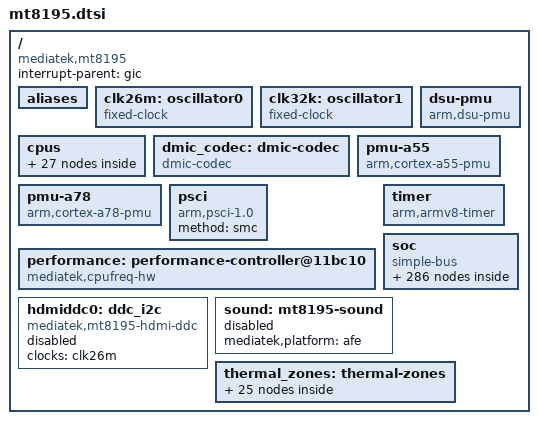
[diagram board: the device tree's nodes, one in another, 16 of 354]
// SPDX-License-Identifier: (GPL-2.0 OR MIT)
/*
 * Copyright (c) 2021 MediaTek Inc.
 * Author: Seiya Wang <seiya.wang@mediatek.com>
 */

/dts-v1/;
#include <dt-bindings/clock/mt8195-clk.h>
#include <dt-bindings/gce/mt8195-gce.h>
#include <dt-bindings/interrupt-controller/arm-gic.h>
#include <dt-bindings/interrupt-controller/irq.h>
#include <dt-bindings/memory/mt8195-memory-port.h>
#include <dt-bindings/phy/phy.h>
#include <dt-bindings/pinctrl/mt8195-pinfunc.h>
#include <dt-bindings/power/mt8195-power.h>
#include <dt-bindings/reset/ti-syscon.h>
#include <dt-bindings/reset/mt8195-resets.h>
#include <dt-bindings/thermal/thermal.h>

/ {
	compatible = "mediatek,mt8195";
	interrupt-parent = <&gic>;
	#address-cells = <2>;
	#size-cells = <2>;

	aliases {
		dpi1 = &disp_dpi1;
		dp-intf0 = &dp_intf0;
		dp-intf1 = &dp_intf1;
		ethdr0 = &ethdr0;
		gce0 = &gce0;
		gce1 = &gce1;
		mutex0 = &mutex;
		mutex1 = &mutex1;
		merge1 = &merge1;
		merge2 = &merge2;
		merge3 = &merge3;
		merge4 = &merge4;
		merge5 = &merge5;
		vdo1_rdma0 = &vdo1_rdma0;
		vdo1_rdma1 = &vdo1_rdma1;
		vdo1_rdma2 = &vdo1_rdma2;
		vdo1_rdma3 = &vdo1_rdma3;
		vdo1_rdma4 = &vdo1_rdma4;
		vdo1_rdma5 = &vdo1_rdma5;
		vdo1_rdma6 = &vdo1_rdma6;
		vdo1_rdma7 = &vdo1_rdma7;
	};

	clk26m: oscillator0 {
		compatible = "fixed-clock";
		#clock-cells = <0>;
		clock-frequency = <26000000>;
		clock-output-names = "clk26m";
	};

	clk32k: oscillator1 {
		compatible = "fixed-clock";
		#clock-cells = <0>;
		clock-frequency = <32768>;
		clock-output-names = "clk32k";
	};

	cpus {
		#address-cells = <1>;
		#size-cells = <0>;

		cpu0: cpu@0 {
			device_type = "cpu";
			compatible = "arm,cortex-a55", "arm,armv8";
			reg = <0x000>;
			enable-method = "psci";
			performance-domains = <&performance 0>;
			clock-frequency = <1701000000>;
			capacity-dmips-mhz = <578>;
			cpu-idle-states = <&cpuoff_l &clusteroff_l>;
			next-level-cache = <&l2_0>;
			#cooling-cells = <2>;
		};

		cpu1: cpu@100 {
			device_type = "cpu";
			compatible = "arm,cortex-a55", "arm,armv8";
			reg = <0x100>;
			enable-method = "psci";
			performance-domains = <&performance 0>;
			clock-frequency = <1701000000>;
			capacity-dmips-mhz = <578>;
			cpu-idle-states = <&cpuoff_l &clusteroff_l>;
			next-level-cache = <&l2_0>;
			#cooling-cells = <2>;
		};

		cpu2: cpu@200 {
			device_type = "cpu";
			compatible = "arm,cortex-a55", "arm,armv8";
			reg = <0x200>;
			enable-method = "psci";
			performance-domains = <&performance 0>;
			clock-frequency = <1701000000>;
			capacity-dmips-mhz = <578>;
			cpu-idle-states = <&cpuoff_l &clusteroff_l>;
			next-level-cache = <&l2_0>;
			#cooling-cells = <2>;
		};

		cpu3: cpu@300 {
			device_type = "cpu";
			compatible = "arm,cortex-a55", "arm,armv8";
			reg = <0x300>;
			enable-method = "psci";
			performance-domains = <&performance 0>;
			clock-frequency = <1701000000>;
			capacity-dmips-mhz = <578>;
			cpu-idle-states = <&cpuoff_l &clusteroff_l>;
			next-level-cache = <&l2_0>;
			#cooling-cells = <2>;
		};

		cpu4: cpu@400 {
			device_type = "cpu";
			compatible = "arm,cortex-a78", "arm,armv8";
			reg = <0x400>;
			enable-method = "psci";
			performance-domains = <&performance 1>;
			clock-frequency = <2171000000>;
			capacity-dmips-mhz = <1024>;
			cpu-idle-states = <&cpuoff_b &clusteroff_b>;
			next-level-cache = <&l2_1>;
			#cooling-cells = <2>;
		};

		cpu5: cpu@500 {
			device_type = "cpu";
			compatible = "arm,cortex-a78", "arm,armv8";
			reg = <0x500>;
			enable-method = "psci";
			performance-domains = <&performance 1>;
			clock-frequency = <2171000000>;
			capacity-dmips-mhz = <1024>;
			cpu-idle-states = <&cpuoff_b &clusteroff_b>;
			next-level-cache = <&l2_1>;
			#cooling-cells = <2>;
		};

		cpu6: cpu@600 {
			device_type = "cpu";
			compatible = "arm,cortex-a78", "arm,armv8";
			reg = <0x600>;
			enable-method = "psci";
			performance-domains = <&performance 1>;
			clock-frequency = <2171000000>;
			capacity-dmips-mhz = <1024>;
			cpu-idle-states = <&cpuoff_b &clusteroff_b>;
			next-level-cache = <&l2_1>;
			#cooling-cells = <2>;
		};

		cpu7: cpu@700 {
			device_type = "cpu";
			compatible = "arm,cortex-a78", "arm,armv8";
			reg = <0x700>;
			enable-method = "psci";
			performance-domains = <&performance 1>;
			clock-frequency = <2171000000>;
			capacity-dmips-mhz = <1024>;
			cpu-idle-states = <&cpuoff_b &clusteroff_b>;
			next-level-cache = <&l2_1>;
			#cooling-cells = <2>;
		};

		cpu-map {
			cluster0 {
				core0 {
					cpu = <&cpu0>;
				};
				core1 {
					cpu = <&cpu1>;
				};
				core2 {
					cpu = <&cpu2>;
				};
				core3 {
					cpu = <&cpu3>;
				};
			};
			cluster1 {
				core0 {
					cpu = <&cpu4>;
				};
				core1 {
					cpu = <&cpu5>;
				};
				core2 {
					cpu = <&cpu6>;
				};
				core3 {
					cpu = <&cpu7>;
				};
			};
		};

		idle-states {
			entry-method = "arm,psci";
			cpuoff_l: cpuoff_l {
				compatible = "arm,idle-state";
				arm,psci-suspend-param = <0x00010001>;
				local-timer-stop;
				entry-latency-us = <50>;
				exit-latency-us = <95>;
				min-residency-us = <580>;
			};
			cpuoff_b: cpuoff_b {
				compatible = "arm,idle-state";
				arm,psci-suspend-param = <0x00010001>;
				local-timer-stop;
				entry-latency-us = <45>;
				exit-latency-us = <140>;
				min-residency-us = <740>;
			};
			clusteroff_l: clusteroff_l {
				compatible = "arm,idle-state";
				arm,psci-suspend-param = <0x01010002>;
				local-timer-stop;
				entry-latency-us = <55>;
				exit-latency-us = <155>;
				min-residency-us = <840>;
			};
			clusteroff_b: clusteroff_b {
				compatible = "arm,idle-state";
				arm,psci-suspend-param = <0x01010002>;
				local-timer-stop;
				entry-latency-us = <50>;
				exit-latency-us = <200>;
				min-residency-us = <1000>;
			};
		};

		l2_0: l2-cache0 {
			compatible = "cache";
			next-level-cache = <&l3_0>;
		};

		l2_1: l2-cache1 {
			compatible = "cache";
			next-level-cache = <&l3_0>;
		};

		l3_0: l3-cache {
			compatible = "cache";
		};
	};

	dsu-pmu {
		compatible = "arm,dsu-pmu";
		interrupts = <GIC_SPI 18 IRQ_TYPE_LEVEL_HIGH 0>;
		cpus = <&cpu0>, <&cpu1>, <&cpu2>, <&cpu3>,
		       <&cpu4>, <&cpu5>, <&cpu6>, <&cpu7>;
	};

	dmic_codec: dmic-codec {
		compatible = "dmic-codec";
		num-channels = <2>;
		wakeup-delay-ms = <50>;
	};

	pmu-a55 {
		compatible = "arm,cortex-a55-pmu";
		interrupt-parent = <&gic>;
		interrupts = <GIC_PPI 7 IRQ_TYPE_LEVEL_HIGH &ppi_cluster0>;
	};

	pmu-a78 {
		compatible = "arm,cortex-a78-pmu";
		interrupt-parent = <&gic>;
		interrupts = <GIC_PPI 7 IRQ_TYPE_LEVEL_HIGH &ppi_cluster1>;
	};

	psci {
		compatible = "arm,psci-1.0";
		method = "smc";
	};

        performance: performance-controller@11bc10 {
                compatible = "mediatek,cpufreq-hw";
                reg = <0 0x0011bc10 0 0x120>, <0 0x0011bd30 0 0x120>;
                #performance-domain-cells = <1>;
        };

	timer: timer {
		compatible = "arm,armv8-timer";
		interrupt-parent = <&gic>;
		interrupts = <GIC_PPI 13 IRQ_TYPE_LEVEL_HIGH 0>,
			     <GIC_PPI 14 IRQ_TYPE_LEVEL_HIGH 0>,
			     <GIC_PPI 11 IRQ_TYPE_LEVEL_HIGH 0>,
			     <GIC_PPI 10 IRQ_TYPE_LEVEL_HIGH 0>;
		clock-frequency = <13000000>;
	};

	soc {
		#address-cells = <2>;
		#size-cells = <2>;
		compatible = "simple-bus";
		ranges;

		gic: interrupt-controller@c000000 {
			compatible = "arm,gic-v3";
			#interrupt-cells = <4>;
			#redistributor-regions = <1>;
			interrupt-parent = <&gic>;
			interrupt-controller;
			reg = <0 0x0c000000 0 0x40000>,
			      <0 0x0c040000 0 0x200000>;
			interrupts = <GIC_PPI 9 IRQ_TYPE_LEVEL_HIGH 0>;

			ppi-partitions {
				ppi_cluster0: interrupt-partition-0 {
					affinity = <&cpu0 &cpu1 &cpu2 &cpu3>;
				};
				ppi_cluster1: interrupt-partition-1 {
					affinity = <&cpu4 &cpu5 &cpu6 &cpu7>;
				};
			};
		};

		topckgen: syscon@10000000 {
			compatible = "mediatek,mt8195-topckgen", "syscon";
			reg = <0 0x10000000 0 0x1000>;
			#clock-cells = <1>;
		};

		infracfg_ao: syscon@10001000 {
			compatible = "mediatek,mt8195-infracfg_ao", "syscon", "simple-mfd";
			reg = <0 0x10001000 0 0x1000>;
			#clock-cells = <1>;
			infracfg_rst: reset-controller {
				compatible = "ti,syscon-reset";
				#reset-cells = <1>;
				ti,reset-bits = <
					0x140 18 0x144 18 0 0 (ASSERT_SET | DEASSERT_SET | STATUS_NONE)
					0x120 0 0x124 0 0 0     (ASSERT_SET | DEASSERT_SET | STATUS_NONE)
					0x730 10 0x734 10 0 0     (ASSERT_SET | DEASSERT_SET | STATUS_NONE)
					0x150 5 0x154 5 0 0     (ASSERT_SET | DEASSERT_SET | STATUS_NONE)
				>;
			};
		};

		pericfg: syscon@10003000 {
			compatible = "mediatek,mt8195-pericfg", "syscon";
			reg = <0 0x10003000 0 0x1000>;
			#clock-cells = <1>;
		};

		pio: pinctrl@10005000 {
			compatible = "mediatek,mt8195-pinctrl";
			reg = <0 0x10005000 0 0x1000>,
			      <0 0x11d10000 0 0x1000>,
			      <0 0x11d30000 0 0x1000>,
			      <0 0x11d40000 0 0x1000>,
			      <0 0x11e20000 0 0x1000>,
			      <0 0x11eb0000 0 0x1000>,
			      <0 0x11f40000 0 0x1000>,
			      <0 0x1000b000 0 0x1000>;
			reg-names = "iocfg0", "iocfg_bm", "iocfg_bl",
				    "iocfg_br", "iocfg_lm", "iocfg_rb",
				    "iocfg_tl", "eint";
			gpio-controller;
			#gpio-cells = <2>;
			gpio-ranges = <&pio 0 0 144>;
			interrupt-controller;
			interrupts = <GIC_SPI 235 IRQ_TYPE_LEVEL_HIGH 0>;
			#interrupt-cells = <2>;
		};

		scpsys: syscon@10006000 {
			compatible = "syscon", "simple-mfd";
			reg = <0 0x10006000 0 0x1000>;
			#power-domain-cells = <1>;

			/* System Power Manager */
			spm: power-controller {
				compatible = "mediatek,mt8195-power-controller";
				#address-cells = <1>;
				#size-cells = <0>;
				#power-domain-cells = <1>;

				/* power domain of the SoC */
				mfg0: power-domain@MT8195_POWER_DOMAIN_MFG0 {
					reg = <MT8195_POWER_DOMAIN_MFG0>;
					#address-cells = <1>;
					#size-cells = <0>;
					#power-domain-cells = <1>;

					power-domain@MT8195_POWER_DOMAIN_MFG1 {
						reg = <MT8195_POWER_DOMAIN_MFG1>;
						clocks = <&apmixedsys CLK_APMIXED_MFGPLL>;
						clock-names = "mfg";
						mediatek,infracfg = <&infracfg_ao>;
						#address-cells = <1>;
						#size-cells = <0>;
						#power-domain-cells = <1>;

						power-domain@MT8195_POWER_DOMAIN_MFG2 {
							reg = <MT8195_POWER_DOMAIN_MFG2>;
							#power-domain-cells = <0>;
						};

						power-domain@MT8195_POWER_DOMAIN_MFG3 {
							reg = <MT8195_POWER_DOMAIN_MFG3>;
							#power-domain-cells = <0>;
						};

						power-domain@MT8195_POWER_DOMAIN_MFG4 {
							reg = <MT8195_POWER_DOMAIN_MFG4>;
							#power-domain-cells = <0>;
						};

						power-domain@MT8195_POWER_DOMAIN_MFG5 {
							reg = <MT8195_POWER_DOMAIN_MFG5>;
							#power-domain-cells = <0>;
						};

						power-domain@MT8195_POWER_DOMAIN_MFG6 {
							reg = <MT8195_POWER_DOMAIN_MFG6>;
							#power-domain-cells = <0>;
						};
					};
				};

				power-domain@MT8195_POWER_DOMAIN_VPPSYS0 {
					reg = <MT8195_POWER_DOMAIN_VPPSYS0>;
					clocks = <&topckgen CLK_TOP_VPP>,
						 <&topckgen CLK_TOP_CAM>,
						 <&topckgen CLK_TOP_CCU>,
						 <&topckgen CLK_TOP_IMG>,
						 <&topckgen CLK_TOP_VENC>,
						 <&topckgen CLK_TOP_VDEC>,
						 <&topckgen CLK_TOP_WPE_VPP>,
						 <&topckgen CLK_TOP_CFG_VPP0>,
						 <&vppsys0 CLK_VPP0_SMI_COMMON>,
						 <&vppsys0 CLK_VPP0_GALS_VDO0_LARB0>,
						 <&vppsys0 CLK_VPP0_GALS_VDO0_LARB1>,
						 <&vppsys0 CLK_VPP0_GALS_VENCSYS>,
						 <&vppsys0 CLK_VPP0_GALS_VENCSYS_CORE1>,
						 <&vppsys0 CLK_VPP0_GALS_INFRA>,
						 <&vppsys0 CLK_VPP0_GALS_CAMSYS>,
						 <&vppsys0 CLK_VPP0_GALS_VPP1_LARB5>,
						 <&vppsys0 CLK_VPP0_GALS_VPP1_LARB6>,
						 <&vppsys0 CLK_VPP0_SMI_REORDER>,
						 <&vppsys0 CLK_VPP0_SMI_IOMMU>,
						 <&vppsys0 CLK_VPP0_GALS_IMGSYS_CAMSYS>,
						 <&vppsys0 CLK_VPP0_GALS_EMI0_EMI1>,
						 <&vppsys0 CLK_VPP0_SMI_SUB_COMMON_REORDER>,
						 <&vppsys0 CLK_VPP0_SMI_RSI>,
						 <&vppsys0 CLK_VPP0_SMI_COMMON_LARB4>,
						 <&vppsys0 CLK_VPP0_GALS_VDEC_VDEC_CORE1>,
						 <&vppsys0 CLK_VPP0_GALS_VPP1_WPE>,
						 <&vppsys0 CLK_VPP0_GALS_VDO0_VDO1_VENCSYS_CORE1>;
					clock-names = "vppsys", "vppsys1", "vppsys2", "vppsys3",
						      "vppsys4", "vppsys5", "vppsys6", "vppsys7",
						      "vppsys0-0", "vppsys0-1", "vppsys0-2", "vppsys0-3",
						      "vppsys0-4", "vppsys0-5", "vppsys0-6", "vppsys0-7",
						      "vppsys0-8", "vppsys0-9", "vppsys0-10", "vppsys0-11",
						      "vppsys0-12", "vppsys0-13", "vppsys0-14",
						      "vppsys0-15", "vppsys0-16", "vppsys0-17",
						      "vppsys0-18";
					mediatek,infracfg = <&infracfg_ao>;
					#address-cells = <1>;
					#size-cells = <0>;
					#power-domain-cells = <1>;

					power-domain@MT8195_POWER_DOMAIN_VDEC1 {
						reg = <MT8195_POWER_DOMAIN_VDEC1>;
						clocks = <&vdecsys CLK_VDEC_LARB1>;
						clock-names = "vdec1-0";
						mediatek,infracfg = <&infracfg_ao>;
						#power-domain-cells = <0>;
					};

					power-domain@MT8195_POWER_DOMAIN_VENC_CORE1 {
						reg = <MT8195_POWER_DOMAIN_VENC_CORE1>;
						mediatek,infracfg = <&infracfg_ao>;
						#power-domain-cells = <0>;
					};

					power-domain@MT8195_POWER_DOMAIN_VDOSYS0 {
						reg = <MT8195_POWER_DOMAIN_VDOSYS0>;
						clocks = <&topckgen CLK_TOP_CFG_VDO0>,
							 <&vdosys0 CLK_VDO0_SMI_GALS>,
							 <&vdosys0 CLK_VDO0_SMI_COMMON>,
							 <&vdosys0 CLK_VDO0_SMI_EMI>,
							 <&vdosys0 CLK_VDO0_SMI_IOMMU>,
							 <&vdosys0 CLK_VDO0_SMI_LARB>,
							 <&vdosys0 CLK_VDO0_SMI_RSI>;
						clock-names = "vdosys0", "vdosys0-0", "vdosys0-1",
							      "vdosys0-2", "vdosys0-3",
							      "vdosys0-4", "vdosys0-5";
						mediatek,infracfg = <&infracfg_ao>;
						#address-cells = <1>;
						#size-cells = <0>;
						#power-domain-cells = <1>;

						power-domain@MT8195_POWER_DOMAIN_VPPSYS1 {
							reg = <MT8195_POWER_DOMAIN_VPPSYS1>;
							clocks = <&topckgen CLK_TOP_CFG_VPP1>,
								 <&vppsys1 CLK_VPP1_VPPSYS1_GALS>,
								 <&vppsys1 CLK_VPP1_VPPSYS1_LARB>;
							clock-names = "vppsys1", "vppsys1-0",
								      "vppsys1-1";
							mediatek,infracfg = <&infracfg_ao>;
							#power-domain-cells = <0>;
						};

						power-domain@MT8195_POWER_DOMAIN_WPESYS {
							reg = <MT8195_POWER_DOMAIN_WPESYS>;
							clocks = <&wpesys CLK_WPE_SMI_LARB7>,
								 <&wpesys CLK_WPE_SMI_LARB8>,
								 <&wpesys CLK_WPE_SMI_LARB7_P>,
								 <&wpesys CLK_WPE_SMI_LARB8_P>;
							clock-names = "wepsys-0", "wepsys-1", "wepsys-2",
								      "wepsys-3";
							mediatek,infracfg = <&infracfg_ao>;
							#power-domain-cells = <0>;
						};

						power-domain@MT8195_POWER_DOMAIN_VDEC0 {
							reg = <MT8195_POWER_DOMAIN_VDEC0>;
							clocks = <&vdecsys_soc CLK_VDEC_SOC_LARB1>;
							clock-names = "vdec0-0";
							mediatek,infracfg = <&infracfg_ao>;
							#power-domain-cells = <0>;
						};

						power-domain@MT8195_POWER_DOMAIN_VDEC2 {
							reg = <MT8195_POWER_DOMAIN_VDEC2>;
							clocks = <&vdecsys_core1 CLK_VDEC_CORE1_LARB1>;
							clock-names = "vdec2-0";
							mediatek,infracfg = <&infracfg_ao>;
							#power-domain-cells = <0>;
						};

						power-domain@MT8195_POWER_DOMAIN_VENC {
							reg = <MT8195_POWER_DOMAIN_VENC>;
							mediatek,infracfg = <&infracfg_ao>;
							#power-domain-cells = <0>;
						};

						power-domain@MT8195_POWER_DOMAIN_VDOSYS1 {
							reg = <MT8195_POWER_DOMAIN_VDOSYS1>;
							clocks = <&topckgen CLK_TOP_CFG_VDO1>,
								 <&vdosys1 CLK_VDO1_SMI_LARB2>,
								 <&vdosys1 CLK_VDO1_SMI_LARB3>,
								 <&vdosys1 CLK_VDO1_GALS>;
							clock-names = "vdosys1", "vdosys1-0",
								      "vdosys1-1", "vdosys1-2";
							mediatek,infracfg = <&infracfg_ao>;
							#address-cells = <1>;
							#size-cells = <0>;
							#power-domain-cells = <1>;

							power-domain@MT8195_POWER_DOMAIN_DP_TX {
								reg = <MT8195_POWER_DOMAIN_DP_TX>;
								mediatek,infracfg = <&infracfg_ao>;
								#power-domain-cells = <0>;
							};

							power-domain@MT8195_POWER_DOMAIN_EPD_TX {
								reg = <MT8195_POWER_DOMAIN_EPD_TX>;
								mediatek,infracfg = <&infracfg_ao>;
								#power-domain-cells = <0>;
							};

							power-domain@MT8195_POWER_DOMAIN_HDMI_TX {
								reg = <MT8195_POWER_DOMAIN_HDMI_TX>;
								clocks = <&topckgen CLK_TOP_HDMI_APB>;
								clock-names = "hdmi_tx";
								#power-domain-cells = <0>;
							};
						};

						power-domain@MT8195_POWER_DOMAIN_IMG {
							reg = <MT8195_POWER_DOMAIN_IMG>;
							clocks = <&imgsys CLK_IMG_LARB9>,
								 <&imgsys CLK_IMG_GALS>;
							clock-names = "img-0", "img-1";
							mediatek,infracfg = <&infracfg_ao>;
							#address-cells = <1>;
							#size-cells = <0>;
							#power-domain-cells = <1>;

							power-domain@MT8195_POWER_DOMAIN_DIP {
								reg = <MT8195_POWER_DOMAIN_DIP>;
								#power-domain-cells = <0>;
							};

							power-domain@MT8195_POWER_DOMAIN_IPE {
								reg = <MT8195_POWER_DOMAIN_IPE>;
								clocks = <&topckgen CLK_TOP_IPE>,
									 <&imgsys CLK_IMG_IPE>,
									 <&ipesys CLK_IPE_SMI_LARB12>;
								clock-names = "ipe", "ipe-0", "ipe-1";
								mediatek,infracfg = <&infracfg_ao>;
								#power-domain-cells = <0>;
							};
						};

						power-domain@MT8195_POWER_DOMAIN_CAM {
							reg = <MT8195_POWER_DOMAIN_CAM>;
							clocks = <&camsys CLK_CAM_LARB13>,
								 <&camsys CLK_CAM_LARB14>,
								 <&camsys CLK_CAM_CAM2MM0_GALS>,
								 <&camsys CLK_CAM_CAM2MM1_GALS>,
								 <&camsys CLK_CAM_CAM2SYS_GALS>;
							clock-names = "cam-0", "cam-1", "cam-2", "cam-3",
								      "cam-4";
							mediatek,infracfg = <&infracfg_ao>;
							#address-cells = <1>;
							#size-cells = <0>;
							#power-domain-cells = <1>;

							power-domain@MT8195_POWER_DOMAIN_CAM_RAWA {
								reg = <MT8195_POWER_DOMAIN_CAM_RAWA>;
								#power-domain-cells = <0>;
							};

							power-domain@MT8195_POWER_DOMAIN_CAM_RAWB {
								reg = <MT8195_POWER_DOMAIN_CAM_RAWB>;
								#power-domain-cells = <0>;
							};

							power-domain@MT8195_POWER_DOMAIN_CAM_MRAW {
								reg = <MT8195_POWER_DOMAIN_CAM_MRAW>;
								#power-domain-cells = <0>;
							};
						};
					};
				};

				power-domain@MT8195_POWER_DOMAIN_PCIE_MAC_P0 {
					reg = <MT8195_POWER_DOMAIN_PCIE_MAC_P0>;
					mediatek,infracfg = <&infracfg_ao>;
					#power-domain-cells = <0>;
				};

				power-domain@MT8195_POWER_DOMAIN_PCIE_MAC_P1 {
					reg = <MT8195_POWER_DOMAIN_PCIE_MAC_P1>;
					mediatek,infracfg = <&infracfg_ao>;
					#power-domain-cells = <0>;
				};

				power-domain@MT8195_POWER_DOMAIN_PCIE_PHY {
					reg = <MT8195_POWER_DOMAIN_PCIE_PHY>;
					#power-domain-cells = <0>;
				};

				power-domain@MT8195_POWER_DOMAIN_SSUSB_PCIE_PHY {
					reg = <MT8195_POWER_DOMAIN_SSUSB_PCIE_PHY>;
					#power-domain-cells = <0>;
				};

				power-domain@MT8195_POWER_DOMAIN_CSI_RX_TOP {
					reg = <MT8195_POWER_DOMAIN_CSI_RX_TOP>;
					clocks = <&topckgen CLK_TOP_SENINF>,
						 <&topckgen CLK_TOP_SENINF2>;
					clock-names = "csi_rx_top", "csi_rx_top1";
					#power-domain-cells = <0>;
				};

				power-domain@MT8195_POWER_DOMAIN_ETHER {
					reg = <MT8195_POWER_DOMAIN_ETHER>;
					clocks = <&pericfg_ao CLK_PERI_AO_ETHERNET_MAC>;
					clock-names = "ether";
					#power-domain-cells = <0>;
				};

				power-domain@MT8195_POWER_DOMAIN_ADSP {
					reg = <MT8195_POWER_DOMAIN_ADSP>;
					clocks = <&topckgen CLK_TOP_ADSP>,
						 <&topckgen CLK_TOP_AUDIO_LOCAL_BUS>;
					clock-names = "adsp", "adsp1";
					#address-cells = <1>;
					#size-cells = <0>;
					mediatek,infracfg = <&infracfg_ao>;
					#power-domain-cells = <1>;

					power-domain@MT8195_POWER_DOMAIN_AUDIO {
						reg = <MT8195_POWER_DOMAIN_AUDIO>;
						clocks = <&topckgen CLK_TOP_A1SYS_HP>,
							 <&topckgen CLK_TOP_AUD_INTBUS>,
							 <&topckgen CLK_TOP_AUDIO_LOCAL_BUS>,
							 <&infracfg_ao CLK_INFRA_AO_AUDIO_26M_B>;
						clock-names = "audio", "audio1", "audio2",
							      "audio3";
						mediatek,infracfg = <&infracfg_ao>;
						#power-domain-cells = <0>;
					};
				};
			};
		};

		watchdog: watchdog@10007000 {
			compatible = "mediatek,mt8195-wdt",
				     "mediatek,mt6589-wdt";
			mediatek,disable-extrst;
			reg = <0 0x10007000 0 0x100>;
		};

		apmixedsys: syscon@1000c000 {
			compatible = "mediatek,mt8195-apmixedsys", "syscon";
			reg = <0 0x1000c000 0 0x1000>;
			#clock-cells = <1>;
		};

		cec: cec@10014000 {
			compatible = "mediatek,mt8195-cec";
			reg = <0 0x10014000 0 0x100>;
			interrupts = <GIC_SPI 680 IRQ_TYPE_LEVEL_HIGH 0>;
			clocks = <&infracfg_ao CLK_INFRA_AO_CEC_66M_H>,
				 <&infracfg_ao CLK_INFRA_AO_CEC_66M_B>,
				 <&infracfg_ao CLK_INFRA_AO_HDMI_32K>,
				 <&infracfg_ao CLK_INFRA_AO_HDMI_26M>;
			clock-names = "cec_66m_h",
				      "cec_66m_b",
				      "hdmi_32k",
				      "hdmi_26m";
			hdmi = <&hdmi0>;
		};

		systimer: timer@10017000 {
			compatible = "mediatek,mt8195-timer",
				     "mediatek,mt6765-timer";
			reg = <0 0x10017000 0 0x1000>;
			interrupts = <GIC_SPI 265 IRQ_TYPE_LEVEL_HIGH 0>;
			clocks = <&topckgen CLK_TOP_CLK26M_D2>;
		};

		pwrap: pwrap@10024000 {
			compatible = "mediatek,mt8195-pwrap", "syscon";
			reg = <0 0x10024000 0 0x1000>;
			reg-names = "pwrap";
			interrupts = <GIC_SPI 243 IRQ_TYPE_LEVEL_HIGH 0>;
			clocks = <&infracfg_ao CLK_INFRA_AO_PMIC_AP>,
				 <&infracfg_ao CLK_INFRA_AO_PMIC_TMR>;
			clock-names = "spi", "wrap";
			assigned-clocks = <&topckgen CLK_TOP_PWRAP_ULPOSC>;
			assigned-clock-parents = <&topckgen CLK_TOP_ULPOSC1_D10>;
		};

		spmi: spmi@10027000 {
			compatible = "mediatek,mt8195-spmi";
			reg = <0 0x10027000 0 0x000e00>,
			      <0 0x10029000 0 0x000100>;
			reg-names = "pmif", "spmimst";
			clocks = <&infracfg_ao CLK_INFRA_AO_PMIC_AP>,
				 <&infracfg_ao CLK_INFRA_AO_PMIC_TMR>,
				 <&topckgen CLK_TOP_SPMI_M_MST>;
			clock-names = "pmif_sys_ck",
				      "pmif_tmr_ck",
				      "spmimst_clk_mux";
			assigned-clocks = <&topckgen CLK_TOP_PWRAP_ULPOSC>;
			assigned-clock-parents = <&topckgen CLK_TOP_ULPOSC1_D10>;
		};

		iommu_infra: infra-iommu@10315000 {
			compatible = "mediatek,mt8195-iommu-infra";
			reg = <0 0x10315000 0 0x5000>;
			interrupts = <GIC_SPI 795 IRQ_TYPE_LEVEL_HIGH 0>,
				     <GIC_SPI 796 IRQ_TYPE_LEVEL_HIGH 0>,
				     <GIC_SPI 797 IRQ_TYPE_LEVEL_HIGH 0>,
				     <GIC_SPI 798 IRQ_TYPE_LEVEL_HIGH 0>,
				     <GIC_SPI 799 IRQ_TYPE_LEVEL_HIGH 0>;
			clocks = <&clk26m>;
			clock-names = "bclk";
			#iommu-cells = <1>;
		};

		gce0: disp_mailbox@10320000 {
			compatible = "mediatek,mt8195-gce";
			reg = <0 0x10320000 0 0x4000>;
			interrupts = <GIC_SPI 226 IRQ_TYPE_LEVEL_HIGH 0>;
			#mbox-cells = <2>;
			clocks = <&infracfg_ao CLK_INFRA_AO_GCE>;
		};

		gce1: mdp_mailbox@10330000 {
			compatible = "mediatek,mt8195-gce";
			reg = <0 0x10330000 0 0x4000>;
			interrupts = <GIC_SPI 228 IRQ_TYPE_LEVEL_HIGH 0>;
			#mbox-cells = <2>;
			clocks = <&infracfg_ao CLK_INFRA_AO_GCE2>;
		};

		scp: scp@10500000 {
			compatible = "mediatek,mt8195-scp";
			reg = <0 0x10500000 0 0x100000>,
			      <0 0x10700000 0 0x8000>,
			      <0 0x10720000 0 0xe0000>;
			reg-names = "sram", "l1tcm", "cfg";
			interrupts = <GIC_SPI 462 IRQ_TYPE_LEVEL_HIGH 0>;
			status = "okay";
		};

		scp_adsp: clock-controller@10720000 {
			compatible = "mediatek,mt8195-scp_adsp";
			reg = <0 0x10720000 0 0x1000>;
			#clock-cells = <1>;
		};

		afe: mt8195-afe-pcm@10890000 {
			compatible = "mediatek,mt8195-audio";
			reg = <0 0x10890000 0 0x10000>;
			mediatek,topckgen = <&topckgen>;
			power-domains = <&spm MT8195_POWER_DOMAIN_AUDIO>;
			interrupts = <GIC_SPI 822 IRQ_TYPE_LEVEL_HIGH 0>;
			clocks = <&clk26m>,
				<&apmixedsys CLK_APMIXED_APLL1>,
				<&apmixedsys CLK_APMIXED_APLL2>,
				<&topckgen CLK_TOP_APLL12_DIV0>,
				<&topckgen CLK_TOP_APLL12_DIV1>,
				<&topckgen CLK_TOP_APLL12_DIV2>,
				<&topckgen CLK_TOP_APLL12_DIV3>,
				<&topckgen CLK_TOP_APLL12_DIV9>,
				<&topckgen CLK_TOP_A1SYS_HP>,
				<&topckgen CLK_TOP_AUD_INTBUS>,
				<&topckgen CLK_TOP_AUDIO_H>,
				<&topckgen CLK_TOP_AUDIO_LOCAL_BUS>,
				<&topckgen CLK_TOP_DPTX_MCK>,
				<&topckgen CLK_TOP_I2SO1_MCK>,
				<&topckgen CLK_TOP_I2SO2_MCK>,
				<&topckgen CLK_TOP_I2SI1_MCK>,
				<&topckgen CLK_TOP_I2SI2_MCK>,
				<&infracfg_ao CLK_INFRA_AO_AUDIO_26M_B>,
				<&scp_adsp CLK_SCP_ADSP_AUDIODSP>;
			clock-names = "clk26m",
				"apll1_ck",
				"apll2_ck",
				"apll12_div0",
				"apll12_div1",
				"apll12_div2",
				"apll12_div3",
				"apll12_div9",
				"a1sys_hp_sel",
				"aud_intbus_sel",
				"audio_h_sel",
				"audio_local_bus_sel",
				"dptx_m_sel",
				"i2so1_m_sel",
				"i2so2_m_sel",
				"i2si1_m_sel",
				"i2si2_m_sel",
				"infra_ao_audio_26m_b",
				"scp_adsp_audiodsp";
			status = "disabled";
		};

		uart0: serial@11001100 {
			compatible = "mediatek,mt8195-uart",
				     "mediatek,mt6577-uart";
			reg = <0 0x11001100 0 0x100>;
			interrupts = <GIC_SPI 141 IRQ_TYPE_LEVEL_HIGH 0>;
			clocks = <&clk26m>, <&infracfg_ao CLK_INFRA_AO_UART0>;
			clock-names = "baud", "bus";
			status = "disabled";
		};

		uart1: serial@11001200 {
			compatible = "mediatek,mt8195-uart",
				     "mediatek,mt6577-uart";
			reg = <0 0x11001200 0 0x100>;
			interrupts = <GIC_SPI 142 IRQ_TYPE_LEVEL_HIGH 0>;
			clocks = <&clk26m>, <&infracfg_ao CLK_INFRA_AO_UART1>;
			clock-names = "baud", "bus";
			status = "disabled";
		};

		uart2: serial@11001300 {
			compatible = "mediatek,mt8195-uart",
				     "mediatek,mt6577-uart";
			reg = <0 0x11001300 0 0x100>;
			interrupts = <GIC_SPI 143 IRQ_TYPE_LEVEL_HIGH 0>;
			clocks = <&clk26m>, <&infracfg_ao CLK_INFRA_AO_UART2>;
			clock-names = "baud", "bus";
			status = "disabled";
		};

		uart3: serial@11001400 {
			compatible = "mediatek,mt8195-uart",
				     "mediatek,mt6577-uart";
			reg = <0 0x11001400 0 0x100>;
			interrupts = <GIC_SPI 723 IRQ_TYPE_LEVEL_HIGH 0>;
			clocks = <&clk26m>, <&infracfg_ao CLK_INFRA_AO_UART3>;
			clock-names = "baud", "bus";
			status = "disabled";
		};

		uart4: serial@11001500 {
			compatible = "mediatek,mt8195-uart",
				     "mediatek,mt6577-uart";
			reg = <0 0x11001500 0 0x100>;
			interrupts = <GIC_SPI 724 IRQ_TYPE_LEVEL_HIGH 0>;
			clocks = <&clk26m>, <&infracfg_ao CLK_INFRA_AO_UART4>;
			clock-names = "baud", "bus";
			status = "disabled";
		};

		uart5: serial@11001600 {
			compatible = "mediatek,mt8195-uart",
				     "mediatek,mt6577-uart";
			reg = <0 0x11001600 0 0x100>;
			interrupts = <GIC_SPI 725 IRQ_TYPE_LEVEL_HIGH 0>;
			clocks = <&clk26m>, <&infracfg_ao CLK_INFRA_AO_UART5>;
			clock-names = "baud", "bus";
			status = "disabled";
		};

		auxadc: auxadc@11002000 {
			compatible = "mediatek,mt8195-auxadc",
				     "mediatek,mt8173-auxadc";
			reg = <0 0x11002000 0 0x1000>;
			clocks = <&infracfg_ao CLK_INFRA_AO_AUXADC>;
			clock-names = "main";
			#io-channel-cells = <1>;
			status = "disabled";
		};

		pericfg_ao: syscon@11003000 {
			compatible = "mediatek,mt8195-pericfg_ao", "syscon";
			reg = <0 0x11003000 0 0x1000>;
			#clock-cells = <1>;
		};

		spi0: spi@1100a000 {
			compatible = "mediatek,mt8195-spi",
				     "mediatek,mt6765-spi";
			#address-cells = <1>;
			#size-cells = <0>;
			reg = <0 0x1100a000 0 0x1000>;
			interrupts = <GIC_SPI 191 IRQ_TYPE_LEVEL_HIGH 0>;
			clocks = <&topckgen CLK_TOP_UNIVPLL_D6_D2>,
				 <&topckgen CLK_TOP_SPI>,
				 <&infracfg_ao CLK_INFRA_AO_SPI0>;
			clock-names = "parent-clk", "sel-clk", "spi-clk";
			status = "disabled";
		};

		lvts: lvts@1100b000 {
			compatible = "mediatek,mt8195-lvts";
			#thermal-sensor-cells = <1>;
			reg = <0 0x1100b000 0 0x1000>,
				<0 0x11278000 0 0x1000>;
			interrupts = <GIC_SPI 169 IRQ_TYPE_LEVEL_HIGH 0>,
					<GIC_SPI 170 IRQ_TYPE_LEVEL_HIGH 0>;
			clocks = <&infracfg_ao CLK_INFRA_AO_THERM>;
			clock-names = "lvts_clk";
			resets = <&infracfg_rst 1>,
					<&infracfg_rst 2>;
			nvmem-cells = <&lvts_e_data1 &lvts_e_data2>;
			nvmem-cell-names = "e_data1","e_data2";
		};

		svs: svs@1100b000 {
			compatible = "mediatek,mt8195-svs";
			reg = <0 0x1100b000 0 0x1000>;
			interrupts = <GIC_SPI 199 IRQ_TYPE_LEVEL_HIGH 0>;
			clocks = <&infracfg_ao CLK_INFRA_AO_THERM>;
			clock-names = "main";
			nvmem-cells = <&svs_calibration>,
				      <&lvts_e_data1>;
			nvmem-cell-names = "svs-calibration-data",
					   "t-calibration-data";
			resets = <&infracfg_rst 3>;
			reset-names = "svs_rst";
		};

		disp_pwm0: disp_pwm0@1100e000 {
			compatible = "mediatek,mt8183-disp-pwm";
			reg = <0 0x1100e000 0 0x1000>;
			interrupts = <GIC_SPI 203 IRQ_TYPE_LEVEL_LOW 0>;
			power-domains = <&spm MT8195_POWER_DOMAIN_VDOSYS0>;
			#pwm-cells = <2>;
			clocks = <&topckgen CLK_TOP_DISP_PWM0>,
					<&infracfg_ao CLK_INFRA_AO_DISP_PWM>;
			clock-names = "main", "mm";
			status = "disabled";
		};

		disp_pwm1: disp_pwm1@1100f000 {
			compatible = "mediatek,mt8183-disp-pwm";
			reg = <0 0x1100f000 0 0x1000>;
			interrupts = <GIC_SPI 793 IRQ_TYPE_LEVEL_HIGH 0>;
			#pwm-cells = <2>;
			clocks = <&topckgen CLK_TOP_DISP_PWM1>,
				<&infracfg_ao CLK_INFRA_AO_DISP_PWM1>;
			clock-names = "main", "mm";
			status = "disabled";
		};

		spi1: spi@11010000 {
			compatible = "mediatek,mt8195-spi",
				     "mediatek,mt6765-spi";
			#address-cells = <1>;
			#size-cells = <0>;
			reg = <0 0x11010000 0 0x1000>;
			interrupts = <GIC_SPI 192 IRQ_TYPE_LEVEL_HIGH 0>;
			clocks = <&topckgen CLK_TOP_UNIVPLL_D6_D2>,
				 <&topckgen CLK_TOP_SPI>,
				 <&infracfg_ao CLK_INFRA_AO_SPI1>;
			clock-names = "parent-clk", "sel-clk", "spi-clk";
			status = "disabled";
		};

		spi2: spi@11012000 {
			compatible = "mediatek,mt8195-spi",
				     "mediatek,mt6765-spi";
			#address-cells = <1>;
			#size-cells = <0>;
			reg = <0 0x11012000 0 0x1000>;
			interrupts = <GIC_SPI 193 IRQ_TYPE_LEVEL_HIGH 0>;
			clocks = <&topckgen CLK_TOP_UNIVPLL_D6_D2>,
				 <&topckgen CLK_TOP_SPI>,
				 <&infracfg_ao CLK_INFRA_AO_SPI2>;
			clock-names = "parent-clk", "sel-clk", "spi-clk";
			status = "disabled";
		};

		spi3: spi@11013000 {
			compatible = "mediatek,mt8195-spi",
				     "mediatek,mt6765-spi";
			#address-cells = <1>;
			#size-cells = <0>;
			reg = <0 0x11013000 0 0x1000>;
			interrupts = <GIC_SPI 194 IRQ_TYPE_LEVEL_HIGH 0>;
			clocks = <&topckgen CLK_TOP_UNIVPLL_D6_D2>,
				 <&topckgen CLK_TOP_SPI>,
				 <&infracfg_ao CLK_INFRA_AO_SPI3>;
			clock-names = "parent-clk", "sel-clk", "spi-clk";
			status = "disabled";
		};

		spi4: spi@11018000 {
			compatible = "mediatek,mt8195-spi",
				     "mediatek,mt6765-spi";
			#address-cells = <1>;
			#size-cells = <0>;
			reg = <0 0x11018000 0 0x1000>;
			interrupts = <GIC_SPI 195 IRQ_TYPE_LEVEL_HIGH 0>;
			clocks = <&topckgen CLK_TOP_UNIVPLL_D6_D2>,
				 <&topckgen CLK_TOP_SPI>,
				 <&infracfg_ao CLK_INFRA_AO_SPI4>;
			clock-names = "parent-clk", "sel-clk", "spi-clk";
			status = "disabled";
		};

		spi5: spi@11019000 {
			compatible = "mediatek,mt8195-spi",
				     "mediatek,mt6765-spi";
			#address-cells = <1>;
			#size-cells = <0>;
			reg = <0 0x11019000 0 0x1000>;
			interrupts = <GIC_SPI 196 IRQ_TYPE_LEVEL_HIGH 0>;
			clocks = <&topckgen CLK_TOP_UNIVPLL_D6_D2>,
				 <&topckgen CLK_TOP_SPI>,
				 <&infracfg_ao CLK_INFRA_AO_SPI5>;
			clock-names = "parent-clk", "sel-clk", "spi-clk";
			status = "disabled";
		};

		spis0: spi@1101d000 {
			compatible = "mediatek,mt8195-spi-slave";
			reg = <0 0x1101d000 0 0x1000>;
			interrupts = <GIC_SPI 197 IRQ_TYPE_LEVEL_HIGH 0>;
			clocks = <&infracfg_ao CLK_INFRA_AO_SPIS0>;
			clock-names = "spi";
			assigned-clocks = <&topckgen CLK_TOP_SPIS>;
			assigned-clock-parents = <&topckgen CLK_TOP_UNIVPLL_D6>;
			status = "disabled";
		};

		spis1: spi@1101e000 {
			compatible = "mediatek,mt8195-spi-slave";
			reg = <0 0x1101e000 0 0x1000>;
			interrupts = <GIC_SPI 198 IRQ_TYPE_LEVEL_HIGH 0>;
			clocks = <&infracfg_ao CLK_INFRA_AO_SPIS1>;
			clock-names = "spi";
			assigned-clocks = <&topckgen CLK_TOP_SPIS>;
			assigned-clock-parents = <&topckgen CLK_TOP_UNIVPLL_D6>;
			status = "disabled";
		};

		xhci0: xhci@11200000 {
			compatible = "mediatek,mt8195-xhci",
				     "mediatek,mtk-xhci";
			reg = <0 0x11200000 0 0x1000>,
			      <0 0x11203e00 0 0x0100>;
			reg-names = "mac", "ippc";
			interrupts-extended = <&gic GIC_SPI 129 IRQ_TYPE_LEVEL_HIGH 0>,
					      <&pio 219 IRQ_TYPE_LEVEL_LOW>;
			interrupt-names = "host", "wakeup";
			phys = <&u2port0 PHY_TYPE_USB2>,
			       <&u3port0 PHY_TYPE_USB3>;
			assigned-clocks = <&topckgen CLK_TOP_USB_TOP>,
					  <&topckgen CLK_TOP_SSUSB_XHCI>;
			assigned-clock-parents = <&topckgen CLK_TOP_UNIVPLL_D5_D4>,
						 <&topckgen CLK_TOP_UNIVPLL_D5_D4>;
			clocks = <&infracfg_ao CLK_INFRA_AO_SSUSB>,
				 <&infracfg_ao CLK_INFRA_AO_SSUSB_XHCI>,
				 <&topckgen CLK_TOP_SSUSB_REF>,
				 <&apmixedsys CLK_APMIXED_USB1PLL>;
			clock-names = "sys_ck", "xhci_ck", "ref_ck", "mcu_ck";
			mediatek,syscon-wakeup = <&pericfg 0x400 103>;
			wakeup-source;
			#address-cells = <2>;
			#size-cells = <2>;
			status = "disabled";
		};

		mmc0: mmc@11230000 {
			compatible = "mediatek,mt8195-mmc",
				     "mediatek,mt8192-mmc",
				     "mediatek,mt8183-mmc";
			reg = <0 0x11230000 0 0x10000>,
			      <0 0x11f50000 0 0x1000>;
			interrupts = <GIC_SPI 131 IRQ_TYPE_LEVEL_HIGH 0>;
			clocks = <&topckgen CLK_TOP_MSDC50_0>,
				 <&infracfg_ao CLK_INFRA_AO_MSDC0>,
				 <&infracfg_ao CLK_INFRA_AO_MSDC0_SRC>;
			clock-names = "source", "hclk", "source_cg";
			status = "disabled";
		};

		mmc1: mmc@11240000 {
			compatible = "mediatek,mt8195-mmc",
				     "mediatek,mt8192-mmc",
				     "mediatek,mt8183-mmc";
			reg = <0 0x11240000 0 0x1000>,
			      <0 0x11c70000 0 0x1000>;
			interrupts = <GIC_SPI 135 IRQ_TYPE_LEVEL_HIGH 0>;
			clocks = <&topckgen CLK_TOP_MSDC30_1>,
				 <&infracfg_ao CLK_INFRA_AO_MSDC1>,
				 <&infracfg_ao CLK_INFRA_AO_MSDC1_SRC>;
			clock-names = "source", "hclk", "source_cg";
			assigned-clocks = <&topckgen CLK_TOP_MSDC30_1>;
			assigned-clock-parents = <&topckgen CLK_TOP_MSDCPLL_D2>;
			status = "disabled";
		};

		mmc2: mmc@11250000 {
			compatible = "mediatek,mt8195-mmc",
				     "mediatek,mt8192-mmc";
			reg = <0 0x11250000 0 0x1000>,
			      <0 0x11e60000 0 0x1000>;
			interrupts = <GIC_SPI 136 IRQ_TYPE_LEVEL_HIGH 0>;
			clocks = <&topckgen CLK_TOP_MSDC30_2>,
				 <&infracfg_ao CLK_INFRA_AO_CG1_MSDC2>,
				 <&infracfg_ao CLK_INFRA_AO_CG3_MSDC2>;
			clock-names = "source", "hclk", "source_cg";
			assigned-clocks = <&topckgen CLK_TOP_MSDC30_2>;
			assigned-clock-parents = <&topckgen CLK_TOP_MSDCPLL_D2>;
			status = "disabled";
		};

		xhci1: xhci1@11290000 {
			compatible = "mediatek,mt8195-xhci",
				     "mediatek,mtk-xhci";
			reg = <0 0x11290000 0 0x1000>,
			      <0 0x11293e00 0 0x0100>;
			reg-names = "mac", "ippc";
			interrupts-extended = <&gic GIC_SPI 530 IRQ_TYPE_LEVEL_HIGH 0>,
					     <&pio 218 IRQ_TYPE_LEVEL_LOW>;
			interrupt-names = "host", "wakeup";
			phys = <&u2port1 PHY_TYPE_USB2>;
			assigned-clocks = <&topckgen CLK_TOP_USB_TOP_1P>,
					  <&topckgen CLK_TOP_SSUSB_XHCI_1P>;
			assigned-clock-parents = <&topckgen CLK_TOP_UNIVPLL_D5_D4>,
						 <&topckgen CLK_TOP_UNIVPLL_D5_D4>;
			clocks = <&pericfg_ao CLK_PERI_AO_SSUSB_1P_BUS>,
				 <&pericfg_ao CLK_PERI_AO_SSUSB_1P_XHCI>,
				 <&topckgen CLK_TOP_SSUSB_P1_REF>,
				 <&apmixedsys CLK_APMIXED_USB1PLL>;
			clock-names = "sys_ck", "xhci_ck", "ref_ck", "mcu_ck";
			mediatek,syscon-wakeup = <&pericfg 0x400 104>;
			wakeup-source;
			mediatek,u3p-dis-msk = <0x1>;
			#address-cells = <2>;
			#size-cells = <2>;
			status = "disabled";
		};

		xhci2: xhci2@112a0000 {
			compatible = "mediatek,mt8195-xhci",
				     "mediatek,mtk-xhci";
			reg = <0 0x112a0000 0 0x1000>,
			      <0 0x112a3e00 0 0x0100>;
			reg-names = "mac", "ippc";
			interrupts = <GIC_SPI 533 IRQ_TYPE_LEVEL_HIGH 0>;
			phys = <&u2port2 PHY_TYPE_USB2>;
			assigned-clocks = <&topckgen CLK_TOP_USB_TOP_2P>,
					  <&topckgen CLK_TOP_SSUSB_XHCI_2P>;
			assigned-clock-parents = <&topckgen CLK_TOP_UNIVPLL_D5_D4>,
						 <&topckgen CLK_TOP_UNIVPLL_D5_D4>;
			clocks = <&pericfg_ao CLK_PERI_AO_SSUSB_2P_BUS>,
				 <&pericfg_ao CLK_PERI_AO_SSUSB_2P_XHCI>,
				 <&topckgen CLK_TOP_SSUSB_P2_REF>;
			clock-names = "sys_ck", "xhci_ck", "ref_ck";
			#address-cells = <2>;
			#size-cells = <2>;
			status = "disabled";
		};

		xhci3: xhci3@112b0000 {
			compatible = "mediatek,mt8195-xhci",
				     "mediatek,mtk-xhci";
			reg = <0 0x112b0000 0 0x1000>,
			      <0 0x112b3e00 0 0x0100>;
			reg-names = "mac", "ippc";
			interrupts-extended = <&gic GIC_SPI 536 IRQ_TYPE_LEVEL_HIGH 0>,
					      <&pio 221 IRQ_TYPE_LEVEL_LOW>;
			interrupts-names = "host", "wakeup";
			phys = <&u2port3 PHY_TYPE_USB2>;
			assigned-clocks = <&topckgen CLK_TOP_USB_TOP_3P>,
					  <&topckgen CLK_TOP_SSUSB_XHCI_3P>;
			assigned-clock-parents = <&topckgen CLK_TOP_UNIVPLL_D5_D4>,
						 <&topckgen CLK_TOP_UNIVPLL_D5_D4>;
			clocks = <&pericfg_ao CLK_PERI_AO_SSUSB_3P_BUS>,
				 <&pericfg_ao CLK_PERI_AO_SSUSB_3P_XHCI>,
				 <&topckgen CLK_TOP_SSUSB_P3_REF>;
			clock-names = "sys_ck", "xhci_ck", "ref_ck";
			mediatek,syscon-wakeup = <&pericfg 0x400 106>;
			wakeup-source;
			usb2-lpm-disable;
			#address-cells = <2>;
			#size-cells = <2>;
			status = "disabled";
		};

		pcie0: pcie@112f0000 {
			compatible = "mediatek,mt8192-pcie",
				     "mediatek,mt8195-pcie";
			device_type = "pci";
			#address-cells = <3>;
			#size-cells = <2>;
			reg = <0 0x112f0000 0 0x4000>;
			reg-names = "pcie-mac";
			interrupts = <GIC_SPI 791 IRQ_TYPE_LEVEL_HIGH 0>;
			bus-range = <0x00 0xff>;
			ranges = <0x81000000 0 0x20000000
				  0x0 0x20000000 0 0x200000>,
				 <0x82000000 0 0x20200000
				  0x0 0x20200000 0 0x3e00000>;

			iommu-map = <0 &iommu_infra IOMMU_PORT_INFRA_PCIE0 0x2>;
			iommu-map-mask = <0x0>;

			status = "disabled";

			clocks = <&infracfg_ao CLK_INFRA_AO_PCIE_PL_P_250M_P0>,
				 <&infracfg_ao CLK_INFRA_AO_PCIE_TL_26M>,
				 <&infracfg_ao CLK_INFRA_AO_PCIE_TL_96M>,
				 <&infracfg_ao CLK_INFRA_AO_PCIE_TL_32K>,
				 <&infracfg_ao CLK_INFRA_AO_PCIE_PERI_26M>,
				 <&pericfg_ao CLK_PERI_AO_PCIE_P0_MEM>;
			assigned-clocks = <&topckgen CLK_TOP_TL>;
			assigned-clock-parents = <&topckgen CLK_TOP_MAINPLL_D4_D4>;

			phys = <&pciephy>;
			phy-names = "pcie-phy";
			power-domains = <&spm MT8195_POWER_DOMAIN_PCIE_MAC_P0>;

			#interrupt-cells = <1>;
			interrupt-map-mask = <0 0 0 7>;
			interrupt-map = <0 0 0 1 &pcie_intc0 0>,
					<0 0 0 2 &pcie_intc0 1>,
					<0 0 0 3 &pcie_intc0 2>,
					<0 0 0 4 &pcie_intc0 3>;
			pcie_intc0: interrupt-controller {
				interrupt-controller;
				#address-cells = <0>;
				#interrupt-cells = <1>;
			};
		};

		pcie1: pcie@112f8000 {
			compatible = "mediatek,mt8192-pcie",
				     "mediatek,mt8195-pcie";
			device_type = "pci";
			#address-cells = <3>;
			#size-cells = <2>;
			reg = <0 0x112f8000 0 0x4000>;
			reg-names = "pcie-mac";
			interrupts = <GIC_SPI 792 IRQ_TYPE_LEVEL_HIGH 0>;
			bus-range = <0x00 0xff>;
			ranges = <0x81000000 0 0x24000000
				  0x0 0x24000000 0 0x200000>,
				 <0x82000000 0 0x24200000
				  0x0 0x24200000 0 0x3e00000>;

			iommu-map = <0 &iommu_infra IOMMU_PORT_INFRA_PCIE1 0x2>;
			iommu-map-mask = <0x0>;

			status = "disabled";

			clocks = <&infracfg_ao CLK_INFRA_AO_PCIE_PL_P_250M_P1>,
				 <&infracfg_ao CLK_INFRA_AO_PCIE_P1_TL_96M>,
				 <&infracfg_ao CLK_INFRA_AO_PCIE_P1_PERI_26M>,
				 <&pericfg_ao CLK_PERI_AO_PCIE_P0_MEM>;
			assigned-clocks = <&topckgen CLK_TOP_TL_P1>;
			assigned-clock-parents = <&topckgen CLK_TOP_MAINPLL_D4_D4>;

			phys = <&u3port1 PHY_TYPE_PCIE>;
			phy-names = "pcie-phy";
			power-domains = <&spm MT8195_POWER_DOMAIN_PCIE_MAC_P1>;

			#interrupt-cells = <1>;
			interrupt-map-mask = <0 0 0 7>;
			interrupt-map = <0 0 0 1 &pcie_intc1 0>,
					<0 0 0 2 &pcie_intc1 1>,
					<0 0 0 3 &pcie_intc1 2>,
					<0 0 0 4 &pcie_intc1 3>;
			pcie_intc1: interrupt-controller {
				interrupt-controller;
				#address-cells = <0>;
				#interrupt-cells = <1>;
			};
		};

		nor_flash: nor@1132c000 {
			compatible = "mediatek,mt8195-nor",
				     "mediatek,mt8173-nor";
			reg = <0 0x1132c000 0 0x1000>;
			interrupts = <GIC_SPI 825 IRQ_TYPE_LEVEL_HIGH 0>;
			clocks = <&topckgen CLK_TOP_SPINOR>,
				 <&pericfg_ao CLK_PERI_AO_FLASHIF_FLASH>,
				 <&pericfg_ao CLK_PERI_AO_FLASHIF_BUS>;
			clock-names = "spi", "sf", "axi";
			#address-cells = <1>;
			#size-cells = <0>;
			status = "disabled";
		};

		efuse: efuse@11c10000 {
			compatible = "mediatek,efuse";
			reg = <0 0x11c10000 0 0x1000>;
			#address-cells = <1>;
			#size-cells = <1>;
			dp_calibration: dp_data {
				reg = <0x1ac 0x10>;
			};
			lvts_e_data1: data1 {
				reg = <0x1bc 0x14>;
			};
			lvts_e_data2: data1-1 {
				reg = <0x1d0 0x38>;
			};
			svs_calibration: calib@580 {
				reg = <0x580 0x64>;
			};
		};

		u3phy2: t-phy@11c40000 {
			compatible = "mediatek,mt8195-tphy", "mediatek,generic-tphy-v3";
			#address-cells = <1>;
			#size-cells = <1>;
			ranges = <0 0 0x11c40000 0x700>;
			status = "disabled";

			u2port2: usb-phy@0 {
				reg = <0x0 0x700>;
				clocks = <&topckgen CLK_TOP_SSUSB_PHY_P2_REF>;
				clock-names = "ref";
				#phy-cells = <1>;
			};
		};

		u3phy3: t-phy@11c50000 {
			compatible = "mediatek,mt8195-tphy", "mediatek,generic-tphy-v3";
			#address-cells = <1>;
			#size-cells = <1>;
			ranges = <0 0 0x11c50000 0x700>;
			status = "disabled";

			u2port3: usb-phy@0 {
				reg = <0x0 0x700>;
				clocks = <&topckgen CLK_TOP_SSUSB_PHY_P3_REF>;
				clock-names = "ref";
				#phy-cells = <1>;
			};
		};

		i2c5: i2c@11d00000 {
			compatible = "mediatek,mt8195-i2c",
				     "mediatek,mt8192-i2c";
			reg = <0 0x11d00000 0 0x1000>,
			      <0 0x10220580 0 0x80>;
			interrupts = <GIC_SPI 154 IRQ_TYPE_LEVEL_HIGH 0>;
			clock-div = <1>;
			clocks = <&imp_iic_wrap_s CLK_IMP_IIC_WRAP_S_I2C5>,
				 <&infracfg_ao CLK_INFRA_AO_APDMA_B>;
			clock-names = "main", "dma";
			#address-cells = <1>;
			#size-cells = <0>;
			status = "disabled";
		};

		i2c6: i2c@11d01000 {
			compatible = "mediatek,mt8195-i2c",
				     "mediatek,mt8192-i2c";
			reg = <0 0x11d01000 0 0x1000>,
			      <0 0x10220600 0 0x80>;
			interrupts = <GIC_SPI 155 IRQ_TYPE_LEVEL_HIGH 0>;
			clock-div = <1>;
			clocks = <&imp_iic_wrap_s CLK_IMP_IIC_WRAP_S_I2C6>,
				 <&infracfg_ao CLK_INFRA_AO_APDMA_B>;
			clock-names = "main", "dma";
			#address-cells = <1>;
			#size-cells = <0>;
			status = "disabled";
		};

		i2c7: i2c@11d02000 {
			compatible = "mediatek,mt8195-i2c",
				     "mediatek,mt8192-i2c";
			reg = <0 0x11d02000 0 0x1000>,
			      <0 0x10220680 0 0x80>;
			interrupts = <GIC_SPI 156 IRQ_TYPE_LEVEL_HIGH 0>;
			clock-div = <1>;
			clocks = <&imp_iic_wrap_s CLK_IMP_IIC_WRAP_S_I2C7>,
				 <&infracfg_ao CLK_INFRA_AO_APDMA_B>;
			clock-names = "main", "dma";
			#address-cells = <1>;
			#size-cells = <0>;
			status = "disabled";
		};

		imp_iic_wrap_s: clock-controller@11d03000 {
			compatible = "mediatek,mt8195-imp_iic_wrap_s";
			reg = <0 0x11d03000 0 0x1000>;
			#clock-cells = <1>;
		};

		hdmi_phy: hdmi-phy@11d5f000 {
			compatible = "mediatek,mt8195-hdmi-phy";
			reg = <0 0x11d5f000 0 0x100>;
			clocks = <&topckgen CLK_TOP_HDMI_XTAL>;
			clock-names = "hdmi_xtal_sel";
			clock-output-names = "hdmi_txpll";
			#clock-cells = <0>;
			#phy-cells = <0>;
			status = "disabled";
		};

		i2c0: i2c@11e00000 {
			compatible = "mediatek,mt8195-i2c",
				     "mediatek,mt8192-i2c";
			reg = <0 0x11e00000 0 0x1000>,
			      <0 0x10220080 0 0x80>;
			interrupts = <GIC_SPI 144 IRQ_TYPE_LEVEL_HIGH 0>;
			clock-div = <1>;
			clocks = <&imp_iic_wrap_w CLK_IMP_IIC_WRAP_W_I2C0>,
				 <&infracfg_ao CLK_INFRA_AO_APDMA_B>;
			clock-names = "main", "dma";
			#address-cells = <1>;
			#size-cells = <0>;
			status = "okay";
		};

		i2c1: i2c@11e01000 {
			compatible = "mediatek,mt8195-i2c",
				     "mediatek,mt8192-i2c";
			reg = <0 0x11e01000 0 0x1000>,
			      <0 0x10220200 0 0x80>;
			interrupts = <GIC_SPI 147 IRQ_TYPE_LEVEL_HIGH 0>;
			clock-div = <1>;
			clocks = <&imp_iic_wrap_w CLK_IMP_IIC_WRAP_W_I2C1>,
				 <&infracfg_ao CLK_INFRA_AO_APDMA_B>;
			clock-names = "main", "dma";
			#address-cells = <1>;
			#size-cells = <0>;
			status = "disabled";
		};

		i2c2: i2c@11e02000 {
			compatible = "mediatek,mt8195-i2c",
				     "mediatek,mt8192-i2c";
			reg = <0 0x11e02000 0 0x1000>,
			      <0 0x10220380 0 0x80>;
			interrupts = <GIC_SPI 150 IRQ_TYPE_LEVEL_HIGH 0>;
			clock-div = <1>;
			clocks = <&imp_iic_wrap_w CLK_IMP_IIC_WRAP_W_I2C2>,
				 <&infracfg_ao CLK_INFRA_AO_APDMA_B>;
			clock-names = "main", "dma";
			#address-cells = <1>;
			#size-cells = <0>;
			status = "disabled";
		};

		i2c3: i2c@11e03000 {
			compatible = "mediatek,mt8195-i2c",
				     "mediatek,mt8192-i2c";
			reg = <0 0x11e03000 0 0x1000>,
			      <0 0x10220480 0 0x80>;
			interrupts = <GIC_SPI 152 IRQ_TYPE_LEVEL_HIGH 0>;
			clock-div = <1>;
			clocks = <&imp_iic_wrap_w CLK_IMP_IIC_WRAP_W_I2C3>,
				 <&infracfg_ao CLK_INFRA_AO_APDMA_B>;
			clock-names = "main", "dma";
			#address-cells = <1>;
			#size-cells = <0>;
			status = "disabled";
		};

		i2c4: i2c@11e04000 {
			compatible = "mediatek,mt8195-i2c",
				     "mediatek,mt8192-i2c";
			reg = <0 0x11e04000 0 0x1000>,
			      <0 0x10220500 0 0x80>;
			interrupts = <GIC_SPI 153 IRQ_TYPE_LEVEL_HIGH 0>;
			clock-div = <1>;
			clocks = <&imp_iic_wrap_w CLK_IMP_IIC_WRAP_W_I2C4>,
				 <&infracfg_ao CLK_INFRA_AO_APDMA_B>;
			clock-names = "main", "dma";
			#address-cells = <1>;
			#size-cells = <0>;
			status = "disabled";
		};

		imp_iic_wrap_w: clock-controller@11e05000 {
			compatible = "mediatek,mt8195-imp_iic_wrap_w";
			reg = <0 0x11e05000 0 0x1000>;
			#clock-cells = <1>;
		};

		u3phy1: t-phy@11e30000 {
			compatible = "mediatek,mt8195-tphy", "mediatek,generic-tphy-v3";
			#address-cells = <1>;
			#size-cells = <1>;
			ranges = <0 0 0x11e30000 0xe00>;
			power-domains = <&spm MT8195_POWER_DOMAIN_SSUSB_PCIE_PHY>;
			status = "disabled";

			u2port1: usb-phy@0 {
				reg = <0x0 0x700>;
				clocks = <&topckgen CLK_TOP_SSUSB_PHY_P1_REF>,
					 <&clk26m>;
				clock-names = "ref", "da_ref";
				#phy-cells = <1>;
			};

			u3port1: usb-phy@700 {
				reg = <0x700 0x700>;
				clocks = <&apmixedsys CLK_APMIXED_PLL_SSUSB26M>,
					 <&topckgen CLK_TOP_SSUSB_PHY_P1_REF>;
				clock-names = "ref", "da_ref";
				#phy-cells = <1>;
			};
		};

		u3phy0: t-phy@11e40000 {
			compatible = "mediatek,mt8195-tphy", "mediatek,generic-tphy-v3";
			#address-cells = <1>;
			#size-cells = <1>;
			ranges = <0 0 0x11e40000 0xe00>;
			status = "disabled";

			u2port0: usb-phy@0 {
				reg = <0x0 0x700>;
				clocks = <&topckgen CLK_TOP_SSUSB_PHY_REF>,
					 <&clk26m>;
				clock-names = "ref", "da_ref";
				#phy-cells = <1>;
			};

			u3port0: usb-phy@700 {
				reg = <0x700 0x700>;
				clocks = <&apmixedsys CLK_APMIXED_PLL_SSUSB26M>,
					 <&topckgen CLK_TOP_SSUSB_PHY_REF>;
				clock-names = "ref", "da_ref";
				#phy-cells = <1>;
			};
		};

		pciephy: phy@11e80000 {
			compatible = "mediatek,mt8195-pcie-phy";
			#address-cells = <2>;
			#size-cells = <2>;
			#phy-cells = <0>;
			reg = <0 0x11e80000 0 0x10000>,
			      <0 0x11e90000 0 0x10000>;
			reg-names = "phy-sif", "phy-ckm";

			power-domains = <&spm MT8195_POWER_DOMAIN_PCIE_PHY>;
			status = "disabled";
		};

		ufsphy: phy@11fa0000 {
			compatible = "mediatek,mt8195-ufsphy", "mediatek,mt8183-ufsphy";
			reg = <0 0x11fa0000 0 0xc000>;
			clocks = <&clk26m>, <&clk26m>;
			clock-names = "unipro", "mp";
			#phy-cells = <0>;
			status = "disabled";
		};

		gpu: mali@13000000 {
			compatible = "mediatek,mt8195-mali", "arm,mali-valhall";
			reg = <0 0x13000000 0 0x4000>;
			interrupts =
				<GIC_SPI 395 IRQ_TYPE_LEVEL_HIGH 0>,
				<GIC_SPI 396 IRQ_TYPE_LEVEL_HIGH 0>,
				<GIC_SPI 397 IRQ_TYPE_LEVEL_HIGH 0>;
			interrupt-names =
				"GPU",
				"MMU",
				"JOB";

			/*
			 * Note: the properties below are not part of the
			 * upstream binding.
			 */
			clocks =
				<&topckgen CLK_TOP_MFG_CK_FAST_REF>,
				<&apmixedsys CLK_APMIXED_MFGPLL>,
				<&apmixedsys CLK_APMIXED_MFGPLL>,
				<&topckgen CLK_TOP_MFG_CORE_TMP>,
				<&mfgcfg CLK_MFG_BG3D>;

			clock-names =
				"clk_mux",
				"clk_pll_src",
				"clk_main_parent",
				"clk_sub_parent",
				"subsys_bg3d";

			power-domains =
				<&spm MT8195_POWER_DOMAIN_MFG2>,
				<&spm MT8195_POWER_DOMAIN_MFG3>,
				<&spm MT8195_POWER_DOMAIN_MFG4>,
				<&spm MT8195_POWER_DOMAIN_MFG5>,
				<&spm MT8195_POWER_DOMAIN_MFG6>;
			power-domain-names = "core0",
				"core1",
				"core2",
				"core3",
				"core4";
		};

		gpu_opp_table: opp_table0 {
			/*
			 * Note: "operating-points-v2-mali" compatible and the
			 * opp-core-mask properties are not part of upstream
			 * binding.
			 */

			compatible = "operating-points-v2", "operating-points-v2-mali";
			opp-shared;

			opp-390000000 {
				opp-hz = /bits/ 64 <390000000>;
				opp-hz-real = /bits/ 64 <390000000>,
					      /bits/ 64 <390000000>;
				opp-microvolt = <625000>,
						<750000>;
			};

			opp-410000000 {
				opp-hz = /bits/ 64 <410000000>;
				opp-hz-real = /bits/ 64 <410000000>,
					      /bits/ 64 <410000000>;
				opp-microvolt = <631250>,
						<750000>;
			};

			opp-431000000 {
				opp-hz = /bits/ 64 <431000000>;
				opp-hz-real = /bits/ 64 <431000000>,
					      /bits/ 64 <431000000>;
				opp-microvolt = <631250>,
						<750000>;
			};

			opp-473000000 {
				opp-hz = /bits/ 64 <473000000>;
				opp-hz-real = /bits/ 64 <473000000>,
					      /bits/ 64 <473000000>;
				opp-microvolt = <637500>,
						<750000>;
			};

			opp-515000000 {
				opp-hz = /bits/ 64 <515000000>;
				opp-hz-real = /bits/ 64 <515000000>,
					      /bits/ 64 <515000000>;
				opp-microvolt = <637500>,
						<750000>;
			};

			opp-556000000 {
				opp-hz = /bits/ 64 <556000000>;
				opp-hz-real = /bits/ 64 <556000000>,
					      /bits/ 64 <556000000>;
				opp-microvolt = <643750>,
						<750000>;
			};

			opp-598000000 {
				opp-hz = /bits/ 64 <598000000>;
				opp-hz-real = /bits/ 64 <598000000>,
					      /bits/ 64 <598000000>;
				opp-microvolt = <650000>,
						<750000>;
			};

			opp-640000000 {
				opp-hz = /bits/ 64 <640000000>;
				opp-hz-real = /bits/ 64 <640000000>,
					      /bits/ 64 <640000000>;
				opp-microvolt = <650000>,
						<750000>;
			};

			opp-670000000 {
				opp-hz = /bits/ 64 <670000000>;
				opp-hz-real = /bits/ 64 <670000000>,
					      /bits/ 64 <670000000>;
				opp-microvolt = <662500>,
						<750000>;
			};

			opp-700000000 {
				opp-hz = /bits/ 64 <700000000>;
				opp-hz-real = /bits/ 64 <700000000>,
					      /bits/ 64 <700000000>;
				opp-microvolt = <675000>,
						<750000>;
			};

			opp-730000000 {
				opp-hz = /bits/ 64 <730000000>;
				opp-hz-real = /bits/ 64 <730000000>,
					      /bits/ 64 <730000000>;
				opp-microvolt = <687500>,
						<750000>;
			};

			opp-760000000 {
				opp-hz = /bits/ 64 <760000000>;
				opp-hz-real = /bits/ 64 <760000000>,
					      /bits/ 64 <760000000>;
				opp-microvolt = <700000>,
						<750000>;
			};

			opp-790000000 {
				opp-hz = /bits/ 64 <790000000>;
				opp-hz-real = /bits/ 64 <790000000>,
					      /bits/ 64 <790000000>;
				opp-microvolt = <712500>,
						<750000>;
			};

			opp-820000000 {
				opp-hz = /bits/ 64 <820000000>;
				opp-hz-real = /bits/ 64 <820000000>,
					      /bits/ 64 <820000000>;
				opp-microvolt = <725000>,
						<750000>;
			};

			opp-850000000 {
				opp-hz = /bits/ 64 <850000000>;
				opp-hz-real = /bits/ 64 <850000000>,
					      /bits/ 64 <850000000>;
				opp-microvolt = <737500>,
						<750000>;
			};

			opp-880000000 {
				opp-hz = /bits/ 64 <880000000>;
				opp-hz-real = /bits/ 64 <880000000>,
					      /bits/ 64 <880000000>;
				opp-microvolt = <750000>,
						<750000>;
			};
		};

		mfgcfg: clock-controller@13fbf000 {
			compatible = "mediatek,mt8195-mfgcfg";
			reg = <0 0x13fbf000 0 0x1000>;
			#clock-cells = <1>;
		};

		vppsys0: clock-controller@14000000 {
			compatible = "mediatek,mt8195-vppsys0";
			reg = <0 0x14000000 0 0x1000>;
			mediatek,gce-client-reg = <&gce1 SUBSYS_1400XXXX 0 0x1000>;
			#clock-cells = <1>;
		};

		mdp3_rdma0: mdp_rdma0@14001000 {
			compatible = "mediatek,mt8195-mdp3",
						"mediatek,mt8183-mdp3-rdma";
			mediatek,scp = <&scp>;
			mediatek,mdp3-id = <0>;
			mdp3-comps = "mediatek,mt8195-mdp3-path1", "mediatek,mt8195-mdp3-path2",
					 "mediatek,mt8195-mdp3-dl1", "mediatek,mt8195-mdp3-dl2",
				     "mediatek,mt8195-mdp3-dl3", "mediatek,mt8195-mdp3-dl4",
				     "mediatek,mt8195-mdp3-dl5", "mediatek,mt8195-mdp3-dl6";
			mdp3-comp-ids = <0 1 0 1 0 0 0 0>;
			reg = <0 0x14001000 0 0x1000>;
			mediatek,gce-client-reg = <&gce1 SUBSYS_1400XXXX 0x1000 0x1000>;
			interrupts = <GIC_SPI 578 IRQ_TYPE_LEVEL_HIGH 0>;
			power-domains = <&spm MT8195_POWER_DOMAIN_VPPSYS0>,
							<&spm MT8195_POWER_DOMAIN_VPPSYS1>;
			iommus = <&iommu_vpp M4U_PORT_L4_MDP_RDMA>,
				 <&iommu_vpp M4U_PORT_L4_MDP_WROT>;
			dma-ranges = <0x2 0x0 0x0 0x40000000 0x1 0x0>; /* 8G - 12G IOVA*/
			clocks = <&vppsys0 CLK_VPP0_MDP_RDMA>,
					<&topckgen CLK_TOP_CFG_VPP0>,
					<&topckgen CLK_TOP_CFG_26M_VPP0>,
					<&vppsys0 CLK_VPP0_WARP0_ASYNC_TX>,
					<&vppsys0 CLK_VPP0_WARP0_RELAY>,
					<&vppsys0 CLK_VPP0_WARP0_MDP_DL_ASYNC>,
					<&vppsys0 CLK_VPP0_WARP1_ASYNC_TX>,
					<&vppsys0 CLK_VPP0_WARP1_RELAY>,
					<&vppsys0 CLK_VPP0_WARP1_MDP_DL_ASYNC>,
					<&vppsys0 CLK_VPP0_VPP02VPP1_RELAY>,
					<&vppsys1 CLK_VPP1_DL_ASYNC>,
					<&vppsys1 CLK_VPP1_VPP0_DL_ASYNC>,
					<&vppsys1 CLK_VPP1_VPP0_DL_RELAY>,
					<&vppsys0 CLK_VPP0_VPP12VPP0_ASYNC>,
					<&vppsys1 CLK_VPP1_VPP0_DL1_RELAY>,
					<&vppsys1 CLK_VPP1_SVPP2_VDO0_DL_RELAY>,
					<&vppsys1 CLK_VPP1_SVPP3_VDO1_DL_RELAY>,
					<&vppsys1 CLK_VPP1_SVPP2_VDO1_DL_RELAY>,
					<&vppsys1 CLK_VPP1_SVPP3_VDO0_DL_RELAY>;
			clock-names = "MDP_RDMA0",
						"TOP_CFG_VPP0",
						"TOP_CFG_26M_VPP0",
						"WARP0_ASYNC_TX",
						"WARP0_RELAY",
						"WARP0_MDP_DL_ASYNC",
						"WARP1_ASYNC_TX",
						"WARP1_RELAY",
						"WARP1_MDP_DL_ASYNC",
						"VPP02VPP1_RELAY",
						"VPP0_DL_ASYNC_VPP1",
						"VPP0_DL_ASYNC_VPP0",
						"VPP0_DL_RELAY",
						"VPP12VPP0_ASYNC",
						"VPP0_DL1_RELAY",
						"SVPP2_VDO0_DL_RELAY",
						"SVPP3_VDO1_DL_RELAY",
						"SVPP2_VDO1_DL_RELAY",
						"SVPP3_VDO0_DL_RELAY";
			mediatek,mmsys2 = <&vppsys1>;
			mediatek,mm-mutex2 = <&vpp1_mutex>;
			mediatek,mmsys = <&vppsys0>;
			mediatek,mm-mutex   = <&vpp0_mutex>;
			mboxes =
				<&gce1 12 CMDQ_THR_PRIO_1>,
				<&gce1 13 CMDQ_THR_PRIO_1>,
				<&gce1 14 CMDQ_THR_PRIO_1>,
				<&gce1 21 CMDQ_THR_PRIO_1>,
				<&gce1 22 CMDQ_THR_PRIO_1>;
			mdp3-rdma0  = <&mdp3_rdma0>;
			mdp3-rdma1  = <&svpp1_mdp3_rdma>;
			mdp3-rdma2  = <&svpp2_mdp3_rdma>;
			mdp3-rdma3  = <&svpp3_mdp3_rdma>;
			mdp3-stitch = <&mdp3_stitch0>;
			mdp3-rsz0   = <&mdp3_rsz0>;
			mdp3-rsz1   = <&svpp1_mdp3_rsz>;
			mdp3-rsz2   = <&svpp2_mdp3_rsz>;
			mdp3-rsz3   = <&svpp3_mdp3_rsz>;
			mdp3-wrot0  = <&mdp3_wrot0>;
			mdp3-wrot1  = <&svpp1_mdp3_wrot>;
			mdp3-wrot2  = <&svpp2_mdp3_wrot>;
			mdp3-wrot3  = <&svpp3_mdp3_wrot>;
			mdp3-tdshp0 = <&mdp3_tdshp0>;
			mdp3-tdshp1 = <&svpp1_mdp3_tdshp>;
			mdp3-tdshp2 = <&svpp2_mdp3_tdshp>;
			mdp3-tdshp3 = <&svpp3_mdp3_tdshp>;
			mdp3-aal0   = <&mdp3_aal0>;
			mdp3-aal1   = <&svpp1_mdp3_aal>;
			mdp3-aal2   = <&svpp2_mdp3_aal>;
			mdp3-aal3   = <&svpp3_mdp3_aal>;
			mdp3-color0 = <&mdp3_color0>;
			mdp3-color1 = <&svpp1_mdp3_color>;
			mdp3-color2 = <&svpp2_mdp3_color>;
			mdp3-color3 = <&svpp3_mdp3_color>;
			mdp3-hdr0   = <&mdp3_hdr0>;
			mdp3-hdr1   = <&svpp1_mdp3_hdr>;
			mdp3-hdr2   = <&svpp2_mdp3_hdr>;
			mdp3-hdr3   = <&svpp3_mdp3_hdr>;
			mdp3-fg0    = <&mdp3_fg0>;
			mdp3-fg1    = <&svpp1_mdp3_fg>;
			mdp3-fg2    = <&svpp2_mdp3_fg>;
			mdp3-fg3    = <&svpp3_mdp3_fg>;
			mdp3-tcc0   = <&mdp3_tcc0>;
			mdp3-tcc1   = <&svpp1_mdp3_tcc>;
			mdp3-ovl0   = <&mdp3_ovl0>;
			mdp3-ovl1   = <&svpp1_mdp3_ovl>;
			mdp3-pad0   = <&mdp3_pad0>;
			mdp3-pad1   = <&svpp1_mdp3_pad>;
			mdp3-pad2   = <&svpp2_mdp3_pad>;
			mdp3-pad3   = <&svpp3_mdp3_pad>;
			mdp3-split  = <&vpp_split0>;
			mdp3-merge2 = <&svpp2_mdp3_merge>;
			mdp3-merge3 = <&svpp3_mdp3_merge>;
		};

		mdp3_fg0: mdp_fg0@14002000 {
			compatible = "mediatek,mt8195-mdp3-fg";
			mediatek,mdp3-id = <0>;
			reg = <0 0x14002000 0 0x1000>;
			mediatek,gce-client-reg = <&gce1 SUBSYS_1400XXXX 0x2000 0x1000>;
			interrupts = <GIC_SPI 579 IRQ_TYPE_LEVEL_HIGH 0>;
			clocks = <&vppsys0 CLK_VPP0_MDP_FG>;
			clock-names = "MDP_FG0";
			power-domains = <&spm MT8195_POWER_DOMAIN_VPPSYS0>;
		};

		mdp3_stitch0: mdp_stich0@14003000 {
			compatible = "mediatek,mt8195-mdp3-stitch";
			mediatek,mdp3-id = <0>;
			reg = <0 0x14003000 0 0x1000>;
			mediatek,gce-client-reg = <&gce1 SUBSYS_1400XXXX 0x3000 0x1000>;
			interrupts = <GIC_SPI 580 IRQ_TYPE_LEVEL_HIGH 0>;
			clocks = <&vppsys0 CLK_VPP0_STITCH>;
			clock-names = "MDP_STITCH";
			power-domains = <&spm MT8195_POWER_DOMAIN_VPPSYS0>;
		};

		mdp3_hdr0: mdp_hdr0@14004000 {
			compatible = "mediatek,mt8195-mdp3-hdr";
			mediatek,mdp3-id = <0>;
			reg = <0 0x14004000 0 0x1000>;
			mediatek,gce-client-reg = <&gce1 SUBSYS_1400XXXX 0x4000 0x1000>;
			interrupts = <GIC_SPI 581 IRQ_TYPE_LEVEL_HIGH 0>;
			clocks = <&vppsys0 CLK_VPP0_MDP_HDR>;
			clock-names = "MDP_HDR0";
			power-domains = <&spm MT8195_POWER_DOMAIN_VPPSYS0>;
		};

		mdp3_aal0: mdp_aal0@14005000 {
			compatible = "mediatek,mt8195-mdp3-aal";
			mediatek,mdp3-id = <0>;
			reg = <0 0x14005000 0 0x1000>;
			mediatek,gce-client-reg = <&gce1 SUBSYS_1400XXXX 0x5000 0x1000>;
			interrupts = <GIC_SPI 582 IRQ_TYPE_LEVEL_HIGH 0>;
			clocks = <&vppsys0 CLK_VPP0_MDP_AAL>;
			clock-names = "MDP_AAL0";
			power-domains = <&spm MT8195_POWER_DOMAIN_VPPSYS0>;
		};

		mdp3_rsz0: mdp_rsz0@14006000 {
			compatible = "mediatek,mt8195-mdp3-rsz", "mediatek,mt8183-mdp3-rsz";
			mediatek,mdp3-id = <0>;
			reg = <0 0x14006000 0 0x1000>;
			mediatek,gce-client-reg = <&gce1 SUBSYS_1400XXXX 0x6000 0x1000>;
			interrupts = <GIC_SPI 583 IRQ_TYPE_LEVEL_HIGH 0>;
			clocks = <&vppsys0 CLK_VPP0_MDP_RSZ>;
			clock-names = "MDP_RSZ0";
			power-domains = <&spm MT8195_POWER_DOMAIN_VPPSYS0>;
		};

		mdp3_tdshp0: mdp_tdshp0@14007000 {
			compatible = "mediatek,mt8195-mdp3-tdshp";
			mediatek,mdp3-id = <0>;
			reg = <0 0x14007000 0 0x1000>;
			mediatek,gce-client-reg = <&gce1 SUBSYS_1400XXXX 0x7000 0x1000>;
			interrupts = <GIC_SPI 584 IRQ_TYPE_LEVEL_HIGH 0>;
			clocks = <&vppsys0 CLK_VPP0_MDP_TDSHP>;
			clock-names = "MDP_TDSHP0";
			power-domains = <&spm MT8195_POWER_DOMAIN_VPPSYS0>;
		};

		mdp3_color0: mdp_color0@14008000 {
			compatible = "mediatek,mt8195-mdp3-color";
			mediatek,mdp3-id = <0>;
			reg = <0 0x14008000 0 0x1000>;
			mediatek,gce-client-reg = <&gce1 SUBSYS_1400XXXX 0x8000 0x1000>;
			interrupts = <GIC_SPI 585 IRQ_TYPE_LEVEL_HIGH 0>;
			clocks = <&vppsys0 CLK_VPP0_MDP_COLOR>;
			clock-names = "MDP_COLOR0";
			power-domains = <&spm MT8195_POWER_DOMAIN_VPPSYS0>;
		};

		mdp3_ovl0: mdp_ovl0@14009000 {
			compatible = "mediatek,mt8195-mdp3-ovl";
			mediatek,mdp3-id = <0>;
			reg = <0 0x14009000 0 0x1000>;
			mediatek,gce-client-reg = <&gce1 SUBSYS_1400XXXX 0x9000 0x1000>;
			interrupts = <GIC_SPI 586 IRQ_TYPE_LEVEL_HIGH 0>;
			clocks = <&vppsys0 CLK_VPP0_MDP_OVL>;
			clock-names = "MDP_OVL0";
			power-domains = <&spm MT8195_POWER_DOMAIN_VPPSYS0>;
		};

		mdp3_pad0: mdp_pad0@1400a000 {
			compatible = "mediatek,mt8195-mdp3-pad";
			mediatek,mdp3-id = <0>;
			reg = <0 0x1400a000 0 0x1000>;
			mediatek,gce-client-reg = <&gce1 SUBSYS_1400XXXX 0xa000 0x1000>;
			interrupts = <GIC_SPI 588 IRQ_TYPE_LEVEL_HIGH 0>;
			clocks = <&vppsys0 CLK_VPP0_PADDING>;
			clock-names = "MDP_PAD0";
			power-domains = <&spm MT8195_POWER_DOMAIN_VPPSYS0>;
		};

		mdp3_tcc0: mdp_tcc0@1400b000 {
			compatible = "mediatek,mt8195-mdp3-tcc";
			mediatek,mdp3-id = <0>;
			reg = <0 0x1400b000 0 0x1000>;
			mediatek,gce-client-reg = <&gce1 SUBSYS_1400XXXX 0xb000 0x1000>;
			interrupts = <GIC_SPI 589 IRQ_TYPE_LEVEL_HIGH 0>;
			clocks = <&vppsys0 CLK_VPP0_MDP_TCC>;
			clock-names = "MDP_TCC0";
			power-domains = <&spm MT8195_POWER_DOMAIN_VPPSYS0>;
		};

		mdp3_wrot0: mdp_wrot0@1400c000 {
			compatible = "mediatek,mt8195-mdp3-wrot", "mediatek,mt8183-mdp3-wrot";
			mediatek,mdp3-id = <0>;
			reg = <0 0x1400c000 0 0x1000>;
			mediatek,gce-client-reg = <&gce1 SUBSYS_1400XXXX 0xc000 0x1000>;
			interrupts = <GIC_SPI 590 IRQ_TYPE_LEVEL_HIGH 0>;
			clocks = <&vppsys0 CLK_VPP0_MDP_WROT>;
			clock-names = "MDP_WROT0";
			iommus = <&iommu_vpp M4U_PORT_L4_MDP_WROT>;
			power-domains = <&spm MT8195_POWER_DOMAIN_VPPSYS0>;
		};

		mmsram: mmsram@1400d000 {
			compatible = "mediatek,mmsram";
			reg = <0 0x1400d000 0 0x1000>,
				  <0 0x1e000000 0 0x260000>;
			mediatek,gce-client-reg = <&gce1 SUBSYS_1400XXXX 0xd000 0x1000>;
			interrupts = <GIC_SPI 591 IRQ_TYPE_LEVEL_HIGH 0>;
			clocks = <&vppsys0 CLK_VPP0_MMSYSRAM_TOP>;
			clock-names = "MMSYSRAM_TOP";
			power-domains = <&spm MT8195_POWER_DOMAIN_VPPSYS0>;
		};

		vpp0_mutex: vpp0_mutex@1400f000 {
			compatible = "mediatek,mt8195-vpp0-mutex";
			reg = <0 0x1400f000 0 0x1000>;
			mediatek,gce-client-reg = <&gce1 SUBSYS_1400XXXX 0xf000 0x1000>;
			interrupts = <GIC_SPI 592 IRQ_TYPE_LEVEL_HIGH 0>;
			#clocks = <&vppsys0 CLK_VPP0_MUTEX>;
			#clock-names = "MDP_MUTEX0";
			clocks = <&vppsys0 CLK_VPP0_MUTEX>;
			clock-names = "MDP_MUTEX0";
			power-domains = <&spm MT8195_POWER_DOMAIN_VPPSYS0>;
			mediatek,gce-events = <CMDQ_EVENT_VPP0_MDP_RDMA_SOF>,
					<CMDQ_EVENT_VPP0_MDP_WROT_SOF>,
					<CMDQ_EVENT_VPP0_MDP_RDMA_FRAME_DONE>,
					<CMDQ_EVENT_VPP0_MDP_WROT_VIDO_WDONE>,
					<CMDQ_EVENT_VPP1_SVPP1_MDP_RDMA_SOF>,
					<CMDQ_EVENT_VPP1_SVPP2_MDP_RDMA_SOF>,
					<CMDQ_EVENT_VPP1_SVPP3_MDP_RDMA_SOF>,
					<CMDQ_EVENT_VPP1_SVPP1_MDP_WROT_SOF>,
					<CMDQ_EVENT_VPP1_SVPP2_MDP_WROT_SOF>,
					<CMDQ_EVENT_VPP1_SVPP3_MDP_WROT_SOF>,
					<CMDQ_EVENT_VPP1_SVPP1_MDP_RDMA_FRAME_DONE>,
					<CMDQ_EVENT_VPP1_SVPP2_MDP_RDMA_FRAME_DONE>,
					<CMDQ_EVENT_VPP1_SVPP3_MDP_RDMA_FRAME_DONE>,
					<CMDQ_EVENT_VPP1_SVPP1_MDP_WROT_FRAME_DONE>,
					<CMDQ_EVENT_VPP1_SVPP2_MDP_WROT_FRAME_DONE>,
					<CMDQ_EVENT_VPP1_SVPP3_MDP_WROT_FRAME_DONE>;
		};

		smi_sub_common_vpp0_vpp1_2x1: smi@14010000 {
			compatible = "mediatek,mt8195-smi-sub-common";
			reg = <0 0x14010000 0 0x1000>;
			clocks = <&vppsys0 CLK_VPP0_GALS_VPP1_WPE>,
			       <&vppsys0 CLK_VPP0_GALS_VPP1_WPE>,
			       <&vppsys0 CLK_VPP0_GALS_VPP1_WPE>;
			clock-names = "apb", "smi", "gals0";
			mediatek,smi = <&smi_common_vpp>;
			mediatek,smi_sub_common;
			power-domains = <&spm MT8195_POWER_DOMAIN_VPPSYS0>;
		};

		smi_sub_common_vdec_vpp0_2x1: smi@14011000 {
			compatible = "mediatek,mt8195-smi-sub-common";
			reg = <0 0x14011000 0 0x1000>;
			clocks = <&vppsys0 CLK_VPP0_GALS_VDEC_VDEC_CORE1>,
			         <&vppsys0 CLK_VPP0_GALS_VDEC_VDEC_CORE1>,
			         <&vppsys0 CLK_VPP0_GALS_VDEC_VDEC_CORE1>;
			clock-names = "apb", "smi", "gals0";
			mediatek,smi = <&smi_common_vpp>;
			mediatek,smi_sub_common;
			power-domains = <&spm MT8195_POWER_DOMAIN_VPPSYS0>;
		};

		smi_common_vpp: smi@14012000 {
			compatible = "mediatek,mt8195-smi-common-vpp";
			mediatek,common-id = <1>;
			reg = <0 0x14012000 0 0x1000>;
			mediatek,gce-client-reg = <&gce1 SUBSYS_1401XXXX 0x2000 0x1000>;
			clocks = <&vppsys0 CLK_VPP0_SMI_COMMON_LARB4>,
			       <&vppsys0 CLK_VPP0_SMI_COMMON_LARB4>,
			       <&vppsys0 CLK_VPP0_SMI_RSI>,
			       <&vppsys0 CLK_VPP0_SMI_RSI>;
			clock-names = "apb", "smi", "gals0", "gals1";
			power-domains = <&spm MT8195_POWER_DOMAIN_VPPSYS0>;
		};

		larb4: larb@14013000 {
			compatible = "mediatek,mt8195-smi-larb";
			reg = <0 0x14013000 0 0x1000>;
			mediatek,gce-client-reg = <&gce1 SUBSYS_1401XXXX 0x3000 0x1000>;
			mediatek,larb-id = <4>;
			mediatek,smi = <&smi_sub_common_vpp0_vpp1_2x1>;
			clocks = <&vppsys0 CLK_VPP0_GALS_VPP1_WPE>,
			       <&vppsys0 CLK_VPP0_SMI_COMMON_LARB4>;
			clock-names = "apb", "smi";
			power-domains = <&spm MT8195_POWER_DOMAIN_VPPSYS0>;
		};

		iommu_vpp: iommu@14018000 {
			compatible = "mediatek,mt8195-iommu-vpp";
			reg = <0 0x14018000 0 0x1000>;
			mediatek,gce-client-reg = <&gce1 SUBSYS_1401XXXX 0x8000 0x1000>;
			mediatek,larbs = <&larb1 &larb3 &larb4 &larb6 &larb8
					  &larb12 &larb14 &larb16 &larb18
					  &larb20 &larb22 &larb23 &larb26
					  &larb27>;
			interrupts = <GIC_SPI 594 IRQ_TYPE_LEVEL_HIGH 0>;
			clocks = <&vppsys0 CLK_VPP0_SMI_IOMMU>;
			clock-names = "bclk";
			#iommu-cells = <1>;
			power-domains = <&spm MT8195_POWER_DOMAIN_VPPSYS0>;
		};

		wpesys: clock-controller@14e00000 {
			compatible = "mediatek,mt8195-wpesys";
			reg = <0 0x14e00000 0 0x1000>;
			#clock-cells = <1>;
		};

		wpesys_vpp0: clock-controller@14e02000 {
			compatible = "mediatek,mt8195-wpesys_vpp0";
			reg = <0 0x14e02000 0 0x1000>;
			#clock-cells = <1>;
		};

		wpesys_vpp1: clock-controller@14e03000 {
			compatible = "mediatek,mt8195-wpesys_vpp1";
			reg = <0 0x14e03000 0 0x1000>;
			#clock-cells = <1>;
		};

		larb7: larb@14e04000 {
			compatible = "mediatek,mt8195-smi-larb";
			reg = <0 0x14e04000 0 0x1000>;
			mediatek,larb-id = <7>;
			mediatek,smi = <&smi_common_vdo>;
			clocks = <&wpesys CLK_WPE_SMI_LARB7>,
				 <&wpesys CLK_WPE_SMI_LARB7>;
			clock-names = "apb", "smi";
			power-domains = <&spm MT8195_POWER_DOMAIN_WPESYS>;
		};

		larb8: larb@14e05000 {
			compatible = "mediatek,mt8195-smi-larb";
			reg = <0 0x14e05000 0 0x1000>;
			mediatek,larb-id = <8>;
			mediatek,smi = <&smi_common_vpp>;
			clocks = <&wpesys CLK_WPE_SMI_LARB8>,
			       <&wpesys CLK_WPE_SMI_LARB8>,
			       <&vppsys0 CLK_VPP0_GALS_VPP1_WPE>;
			clock-names = "apb", "smi", "gals";
			power-domains = <&spm MT8195_POWER_DOMAIN_WPESYS>;
		};

		vppsys1: clock-controller@14f00000 {
			compatible = "mediatek,mt8195-vppsys1";
			reg = <0 0x14f00000 0 0x1000>;
			mediatek,gce-client-reg = <&gce1 SUBSYS_14f0XXXX 0 0x1000>;
			#clock-cells = <1>;
		};

		vpp1_mutex: vpp1_mutex@14f01000 {
			compatible = "mediatek,mt8195-vpp1-mutex";
			reg = <0 0x14f01000 0 0x1000>;
			mediatek,gce-client-reg = <&gce1 SUBSYS_14f0XXXX 0x1000 0x1000>;
			interrupts = <GIC_SPI 635 IRQ_TYPE_LEVEL_HIGH 0>;
			#clocks = <&vppsys1 CLK_VPP1_DISP_MUTEX>;
			#clock-names = "DISP_MUTEX";
			clocks = <&vppsys1 CLK_VPP1_DISP_MUTEX>;
			clock-names = "DISP_MUTEX";
			power-domains = <&spm MT8195_POWER_DOMAIN_VPPSYS1>;
		};

		larb5: larb@14f02000 {
			compatible = "mediatek,mt8195-smi-larb";
			reg = <0 0x14f02000 0 0x1000>;
			mediatek,gce-client-reg = <&gce1 SUBSYS_14f0XXXX 0x2000 0x1000>;
			mediatek,larb-id = <5>;
			mediatek,smi = <&smi_common_vdo>;
			clocks = <&vppsys1 CLK_VPP1_VPPSYS1_LARB>,
			       <&vppsys1 CLK_VPP1_VPPSYS1_GALS>,
			       <&vppsys0 CLK_VPP0_GALS_VPP1_LARB5>;
			clock-names = "apb", "smi", "gals";
			power-domains = <&spm MT8195_POWER_DOMAIN_VPPSYS1>;
		};

		larb6: larb@14f03000 {
			compatible = "mediatek,mt8195-smi-larb";
			reg = <0 0x14f03000 0 0x1000>;
			mediatek,gce-client-reg = <&gce1 SUBSYS_14f0XXXX 0x3000 0x1000>;
			mediatek,larb-id = <6>;
			mediatek,smi = <&smi_sub_common_vpp0_vpp1_2x1>;
			clocks = <&vppsys0 CLK_VPP0_GALS_VPP1_WPE>,
			       <&vppsys1 CLK_VPP1_VPPSYS1_LARB>,
			       <&vppsys1 CLK_VPP1_VPPSYS1_GALS>,
			       <&vppsys0 CLK_VPP0_GALS_VPP1_LARB6>;
			clock-names = "apb", "smi", "gals", "gals1";
			power-domains = <&spm MT8195_POWER_DOMAIN_VPPSYS1>;
		};

		vpp_split0: vpp_split0@14f06000 {
			compatible = "mediatek,mt8195-mdp3-split";
			mediatek,mdp3-id = <1>;
			reg = <0 0x14f06000 0 0x1000>;
			mediatek,gce-client-reg = <&gce1 SUBSYS_14f0XXXX 0x6000 0x1000>;
			interrupts = <GIC_SPI 605 IRQ_TYPE_LEVEL_HIGH 0>,
				<GIC_SPI 606 IRQ_TYPE_LEVEL_HIGH 0>;
			clocks = <&vppsys1 CLK_VPP1_VPP_SPLIT>,
					<&vppsys1 CLK_VPP1_HDMI_META>,
					<&vppsys1 CLK_VPP1_VPP_SPLIT_HDMI>,
					<&vppsys1 CLK_VPP1_DGI_IN>,
					<&vppsys1 CLK_VPP1_DGI_OUT>,
					<&vppsys1 CLK_VPP1_VPP_SPLIT_DGI>,
					<&vppsys1 CLK_VPP1_VPP_SPLIT_26M>;
			clock-names = "MDP_SPLIT",
						"HDMI_META",
						"SPLIT_HDMI",
						"DGI_IN",
						"DGI_OUT",
						"SPLIT_DGI",
						"VPP_SPLIT_26M";
			power-domains = <&spm MT8195_POWER_DOMAIN_VPPSYS1>;
		};

		svpp1_mdp3_tcc: svpp1_mdp_tcc@14f07000 {
			compatible = "mediatek,mt8195-mdp3-tcc";
			mediatek,mdp3-id = <1>;
			reg = <0 0x14f07000 0 0x1000>;
			mediatek,gce-client-reg = <&gce1 SUBSYS_14f0XXXX 0x7000 0x1000>;
			interrupts = <GIC_SPI 607 IRQ_TYPE_LEVEL_HIGH 0>;
			clocks = <&vppsys1 CLK_VPP1_SVPP1_MDP_TCC>;
			clock-names = "MDP_TCC1";
			power-domains = <&spm MT8195_POWER_DOMAIN_VPPSYS1>;
		};

		svpp1_mdp3_rdma: svpp1_mdp_rdma@14f08000 {
			compatible = "mediatek,mt8195-mdp3",
				 "mediatek,mt8183-mdp3-rdma";
			mediatek,mdp3-id = <1>;
			reg = <0 0x14f08000 0 0x1000>;
			mediatek,gce-client-reg = <&gce1 SUBSYS_14f0XXXX 0x8000 0x1000>;
			interrupts = <GIC_SPI 608 IRQ_TYPE_LEVEL_HIGH 0>;
			clocks = <&vppsys1 CLK_VPP1_SVPP1_MDP_RDMA>,
					<&topckgen CLK_TOP_CFG_VPP1>,
					<&topckgen CLK_TOP_CFG_26M_VPP1>;
			clock-names = "MDP_RDMA1",
						"TOP_CFG_VPP1",
						"TOP_CFG_26M_VPP1";
			iommus = <&iommu_vdo M4U_PORT_L5_SVPP1_MDP_RDMA>,
				 <&iommu_vdo M4U_PORT_L5_SVPP1_MDP_WROT>;
			dma-ranges = <0x2 0x0 0x0 0x40000000 0x1 0x0>; /* 8G - 12G IOVA*/
			power-domains = <&spm MT8195_POWER_DOMAIN_VPPSYS1>;
		};

		svpp2_mdp3_rdma: svpp2_mdp_rdma@14f09000 {
			compatible = "mediatek,mt8195-mdp3",
				 "mediatek,mt8183-mdp3-rdma";
			mediatek,mdp3-id = <2>;
			reg = <0 0x14f09000 0 0x1000>;
			mediatek,gce-client-reg = <&gce1 SUBSYS_14f0XXXX 0x9000 0x1000>;
			interrupts = <GIC_SPI 609 IRQ_TYPE_LEVEL_HIGH 0>;
			clocks = <&vppsys1 CLK_VPP1_SVPP2_MDP_RDMA>,
					<&topckgen CLK_TOP_CFG_VPP1>,
					<&topckgen CLK_TOP_CFG_26M_VPP1>;
			clock-names = "MDP_RDMA2",
						"TOP_CFG_VPP1",
						"TOP_CFG_26M_VPP1";
			iommus = <&iommu_vdo M4U_PORT_L5_SVPP2_MDP_RDMA>,
				 <&iommu_vdo M4U_PORT_L5_SVPP2_MDP_WROT>;
			dma-ranges = <0x2 0x0 0x0 0x40000000 0x1 0x0>; /* 8G - 12G IOVA*/
			power-domains = <&spm MT8195_POWER_DOMAIN_VPPSYS1>;
		};

		svpp3_mdp3_rdma: svpp3_mdp_rdma@14f0a000 {
			compatible = "mediatek,mt8195-mdp3",
				 "mediatek,mt8183-mdp3-rdma";
			mediatek,mdp3-id = <3>;
			reg = <0 0x14f0a000 0 0x1000>;
			mediatek,gce-client-reg = <&gce1 SUBSYS_14f0XXXX 0xa000 0x1000>;
			interrupts = <GIC_SPI 610 IRQ_TYPE_LEVEL_HIGH 0>;
			clocks = <&vppsys1 CLK_VPP1_SVPP3_MDP_RDMA>,
					<&topckgen CLK_TOP_CFG_VPP1>,
					<&topckgen CLK_TOP_CFG_26M_VPP1>;
			clock-names = "MDP_RDMA3",
						"TOP_CFG_VPP1",
						"TOP_CFG_26M_VPP1";
			iommus = <&iommu_vpp M4U_PORT_L6_SVPP3_MDP_RDMA>,
				 <&iommu_vpp M4U_PORT_L6_SVPP3_MDP_WROT>;
			dma-ranges = <0x2 0x0 0x0 0x40000000 0x1 0x0>; /* 8G - 12G IOVA*/
			power-domains = <&spm MT8195_POWER_DOMAIN_VPPSYS1>;
		};

		svpp1_mdp3_fg: svpp1_mdp_fg@14f0b000 {
			compatible = "mediatek,mt8195-mdp3-fg";
			mediatek,mdp3-id = <1>;
			reg = <0 0x14f0b000 0 0x1000>;
			mediatek,gce-client-reg = <&gce1 SUBSYS_14f0XXXX 0xb000 0x1000>;
			interrupts = <GIC_SPI 611 IRQ_TYPE_LEVEL_HIGH 0>;
			clocks = <&vppsys1 CLK_VPP1_SVPP1_MDP_FG>;
			clock-names = "MDP_FG1";
			power-domains = <&spm MT8195_POWER_DOMAIN_VPPSYS1>;
		};

		svpp2_mdp3_fg: svpp2_mdp_fg@14f0c000 {
			compatible = "mediatek,mt8195-mdp3-fg";
			mediatek,mdp3-id = <2>;
			reg = <0 0x14f0c000 0 0x1000>;
			mediatek,gce-client-reg = <&gce1 SUBSYS_14f0XXXX 0xc000 0x1000>;
			interrupts = <GIC_SPI 612 IRQ_TYPE_LEVEL_HIGH 0>;
			clocks = <&vppsys1 CLK_VPP1_SVPP2_MDP_FG>;
			clock-names = "MDP_FG2";
			power-domains = <&spm MT8195_POWER_DOMAIN_VPPSYS1>;
		};

		svpp3_mdp3_fg: svpp3_mdp_fg@14f0d000 {
			compatible = "mediatek,mt8195-mdp3-fg";
			mediatek,mdp3-id = <3>;
			reg = <0 0x14f0d000 0 0x1000>;
			mediatek,gce-client-reg = <&gce1 SUBSYS_14f0XXXX 0xd000 0x1000>;
			interrupts = <GIC_SPI 613 IRQ_TYPE_LEVEL_HIGH 0>;
			clocks = <&vppsys1 CLK_VPP1_SVPP3_MDP_FG>;
			clock-names = "MDP_FG3";
			power-domains = <&spm MT8195_POWER_DOMAIN_VPPSYS1>;
		};

		svpp1_mdp3_hdr: svpp1_mdp_hdr@14f0e000 {
			compatible = "mediatek,mt8195-mdp3-hdr";
			mediatek,mdp3-id = <1>;
			reg = <0 0x14f0e000 0 0x1000>;
			mediatek,gce-client-reg = <&gce1 SUBSYS_14f0XXXX 0xe000 0x1000>;
			interrupts = <GIC_SPI 614 IRQ_TYPE_LEVEL_HIGH 0>;
			clocks = <&vppsys1 CLK_VPP1_SVPP1_MDP_HDR>;
			clock-names = "MDP_HDR1";
			power-domains = <&spm MT8195_POWER_DOMAIN_VPPSYS1>;
		};

		svpp2_mdp3_hdr: svpp2_mdp_hdr@14f0f000 {
			compatible = "mediatek,mt8195-mdp3-hdr";
			mediatek,mdp3-id = <2>;
			reg = <0 0x14f0f000 0 0x1000>;
			mediatek,gce-client-reg = <&gce1 SUBSYS_14f0XXXX 0xf000 0x1000>;
			interrupts = <GIC_SPI 615 IRQ_TYPE_LEVEL_HIGH 0>;
			clocks = <&vppsys1 CLK_VPP1_SVPP2_MDP_HDR>;
			clock-names = "MDP_HDR2";
			power-domains = <&spm MT8195_POWER_DOMAIN_VPPSYS1>;
		};

		svpp3_mdp3_hdr: svpp3_mdp_hdr@14f10000 {
			compatible = "mediatek,mt8195-mdp3-hdr";
			mediatek,mdp3-id = <3>;
			reg = <0 0x14f10000 0 0x1000>;
			mediatek,gce-client-reg = <&gce1 SUBSYS_14f1XXXX 0 0x1000>;
			interrupts = <GIC_SPI 616 IRQ_TYPE_LEVEL_HIGH 0>;
			clocks = <&vppsys1 CLK_VPP1_SVPP3_MDP_HDR>;
			clock-names = "MDP_HDR3";
			power-domains = <&spm MT8195_POWER_DOMAIN_VPPSYS1>;
		};

		svpp1_mdp3_aal: svpp1_mdp_aal@14f11000 {
			compatible = "mediatek,mt8195-mdp3-aal";
			mediatek,mdp3-id = <1>;
			reg = <0 0x14f11000 0 0x1000>;
			mediatek,gce-client-reg = <&gce1 SUBSYS_14f1XXXX 0x1000 0x1000>;
			interrupts = <GIC_SPI 617 IRQ_TYPE_LEVEL_HIGH 0>;
			clocks = <&vppsys1 CLK_VPP1_SVPP1_MDP_AAL>;
			clock-names = "MDP_AAL1";
			power-domains = <&spm MT8195_POWER_DOMAIN_VPPSYS1>;
		};

		svpp2_mdp3_aal: svpp2_mdp_aal@14f12000 {
			compatible = "mediatek,mt8195-mdp3-aal";
			mediatek,mdp3-id = <2>;
			reg = <0 0x14f12000 0 0x1000>;
			mediatek,gce-client-reg = <&gce1 SUBSYS_14f1XXXX 0x2000 0x1000>;
			interrupts = <GIC_SPI 618 IRQ_TYPE_LEVEL_HIGH 0>;
			clocks = <&vppsys1 CLK_VPP1_SVPP2_MDP_AAL>;
			clock-names = "MDP_AAL2";
			power-domains = <&spm MT8195_POWER_DOMAIN_VPPSYS1>;
		};

		svpp3_mdp3_aal: svpp3_mdp_aal@14f13000 {
			compatible = "mediatek,mt8195-mdp3-aal";
			mediatek,mdp3-id = <3>;
			reg = <0 0x14f13000 0 0x1000>;
			mediatek,gce-client-reg = <&gce1 SUBSYS_14f1XXXX 0x3000 0x1000>;
			interrupts = <GIC_SPI 619 IRQ_TYPE_LEVEL_HIGH 0>;
			clocks = <&vppsys1 CLK_VPP1_SVPP3_MDP_AAL>;
			clock-names = "MDP_AAL3";
			power-domains = <&spm MT8195_POWER_DOMAIN_VPPSYS1>;
		};

		svpp1_mdp3_rsz: svpp1_mdp_rsz@14f14000 {
			compatible = "mediatek,mt8195-mdp3-rsz", "mediatek,mt8183-mdp3-rsz";
			mediatek,mdp3-id = <1>;
			reg = <0 0x14f14000 0 0x1000>;
			mediatek,gce-client-reg = <&gce1 SUBSYS_14f1XXXX 0x4000 0x1000>;
			interrupts = <GIC_SPI 620 IRQ_TYPE_LEVEL_HIGH 0>;
			clocks = <&vppsys1 CLK_VPP1_SVPP1_MDP_RSZ>;
			clock-names = "MDP_RSZ1";
			power-domains = <&spm MT8195_POWER_DOMAIN_VPPSYS1>;
		};

		svpp2_mdp3_rsz: svpp2_mdp_rsz@14f15000 {
			compatible = "mediatek,mt8195-mdp3-rsz", "mediatek,mt8183-mdp3-rsz";
			mediatek,mdp3-id = <2>;
			reg = <0 0x14f15000 0 0x1000>;
			mediatek,gce-client-reg = <&gce1 SUBSYS_14f1XXXX 0x5000 0x1000>;
			interrupts = <GIC_SPI 621 IRQ_TYPE_LEVEL_HIGH 0>;
			clocks = <&vppsys1 CLK_VPP1_SVPP2_MDP_RSZ>,
					<&vppsys1 CLK_VPP1_SVPP2_VPP_MERGE>;
			clock-names = "MDP_RSZ2";
			power-domains = <&spm MT8195_POWER_DOMAIN_VPPSYS1>;
		};

		svpp3_mdp3_rsz: svpp3_mdp_rsz@14f16000 {
			compatible = "mediatek,mt8195-mdp3-rsz", "mediatek,mt8183-mdp3-rsz";
			mediatek,mdp3-id = <3>;
			reg = <0 0x14f16000 0 0x1000>;
			mediatek,gce-client-reg = <&gce1 SUBSYS_14f1XXXX 0x6000 0x1000>;
			interrupts = <GIC_SPI 622 IRQ_TYPE_LEVEL_HIGH 0>;
			clocks = <&vppsys1 CLK_VPP1_SVPP3_MDP_RSZ>,
					<&vppsys1 CLK_VPP1_SVPP3_VPP_MERGE>;
			clock-names = "MDP_RSZ3";
			power-domains = <&spm MT8195_POWER_DOMAIN_VPPSYS1>;
		};

		svpp1_mdp3_tdshp: svpp1_mdp_tdshp@14f17000 {
			compatible = "mediatek,mt8195-mdp3-tdshp";
			mediatek,mdp3-id = <1>;
			reg = <0 0x14f17000 0 0x1000>;
			mediatek,gce-client-reg = <&gce1 SUBSYS_14f1XXXX 0x7000 0x1000>;
			interrupts = <GIC_SPI 623 IRQ_TYPE_LEVEL_HIGH 0>;
			clocks = <&vppsys1 CLK_VPP1_SVPP1_MDP_TDSHP>;
			clock-names = "MDP_TDSHP1";
			power-domains = <&spm MT8195_POWER_DOMAIN_VPPSYS1>;
		};

		svpp2_mdp3_tdshp: svpp2_mdp_tdshp@14f18000 {
			compatible = "mediatek,mt8195-mdp3-tdshp";
			mediatek,mdp3-id = <2>;
			reg = <0 0x14f18000 0 0x1000>;
			mediatek,gce-client-reg = <&gce1 SUBSYS_14f1XXXX 0x8000 0x1000>;
			interrupts = <GIC_SPI 624 IRQ_TYPE_LEVEL_HIGH 0>;
			clocks = <&vppsys1 CLK_VPP1_SVPP2_MDP_TDSHP>;
			clock-names = "MDP_TDSHP2";
			power-domains = <&spm MT8195_POWER_DOMAIN_VPPSYS1>;
		};

		svpp3_mdp3_tdshp: svpp3_mdp_tdshp@14f19000 {
			compatible = "mediatek,mt8195-mdp3-tdshp";
			mediatek,mdp3-id = <3>;
			reg = <0 0x14f19000 0 0x1000>;
			mediatek,gce-client-reg = <&gce1 SUBSYS_14f1XXXX 0x9000 0x1000>;
			interrupts = <GIC_SPI 625 IRQ_TYPE_LEVEL_HIGH 0>;
			clocks = <&vppsys1 CLK_VPP1_SVPP3_MDP_TDSHP>;
			clock-names = "MDP_TDSHP3";
			power-domains = <&spm MT8195_POWER_DOMAIN_VPPSYS1>;
		};

		svpp2_mdp3_merge: svpp2_mdp_merge@14f1a000 {
			compatible = "mediatek,mt8195-mdp3-merge";
			mediatek,mdp3-id = <2>;
			reg = <0 0x14f1a000 0 0x1000>;
			mediatek,gce-client-reg = <&gce1 SUBSYS_14f1XXXX 0xa000 0x1000>;
			interrupts = <GIC_SPI 626 IRQ_TYPE_LEVEL_HIGH 0>;
			clocks = <&vppsys1 CLK_VPP1_SVPP2_VPP_MERGE>;
			clock-names = "MDP_MERGE2";
			power-domains = <&spm MT8195_POWER_DOMAIN_VPPSYS1>;
		};

		svpp3_mdp3_merge: svpp3_mdp_merge@14f1b000 {
			compatible = "mediatek,mt8195-mdp3-merge";
			mediatek,mdp3-id = <3>;
			reg = <0 0x14f1b000 0 0x1000>;
			mediatek,gce-client-reg = <&gce1 SUBSYS_14f1XXXX 0xb000 0x1000>;
			interrupts = <GIC_SPI 627 IRQ_TYPE_LEVEL_HIGH 0>;
			clocks = <&vppsys1 CLK_VPP1_SVPP3_VPP_MERGE>;
			clock-names = "MDP_MERGE3";
			power-domains = <&spm MT8195_POWER_DOMAIN_VPPSYS1>;
		};

		svpp1_mdp3_color: svpp1_mdp_color@14f1c000 {
			compatible = "mediatek,mt8195-mdp3-color";
			mediatek,mdp3-id = <1>;
			reg = <0 0x14f1c000 0 0x1000>;
			mediatek,gce-client-reg = <&gce1 SUBSYS_14f1XXXX 0xc000 0x1000>;
			interrupts = <GIC_SPI 628 IRQ_TYPE_LEVEL_HIGH 0>;
			clocks = <&vppsys1 CLK_VPP1_SVPP1_MDP_COLOR>;
			clock-names = "MDP_COLOR1";
			power-domains = <&spm MT8195_POWER_DOMAIN_VPPSYS1>;
		};

		svpp2_mdp3_color: svpp2_mdp_color@14f1d000 {
			compatible = "mediatek,mt8195-mdp3-color";
			mediatek,mdp3-id = <2>;
			reg = <0 0x14f1d000 0 0x1000>;
			mediatek,gce-client-reg = <&gce1 SUBSYS_14f1XXXX 0xd000 0x1000>;
			interrupts = <GIC_SPI 629 IRQ_TYPE_LEVEL_HIGH 0>;
			clocks = <&vppsys1 CLK_VPP1_SVPP2_MDP_COLOR>;
			clock-names = "MDP_COLOR2";
			power-domains = <&spm MT8195_POWER_DOMAIN_VPPSYS1>;
		};

		svpp3_mdp3_color: svpp3_mdp_color@14f1e000 {
			compatible = "mediatek,mt8195-mdp3-color";
			mediatek,mdp3-id = <3>;
			reg = <0 0x14f1e000 0 0x1000>;
			mediatek,gce-client-reg = <&gce1 SUBSYS_14f1XXXX 0xe000 0x1000>;
			interrupts = <GIC_SPI 630 IRQ_TYPE_LEVEL_HIGH 0>;
			clocks = <&vppsys1 CLK_VPP1_SVPP3_MDP_COLOR>;
			clock-names = "MDP_COLOR3";
			power-domains = <&spm MT8195_POWER_DOMAIN_VPPSYS1>;
		};

		svpp1_mdp3_ovl: svpp1_mdp_ovl@14f1f000 {
			compatible = "mediatek,mt8195-mdp3-ovl";
			mediatek,mdp3-id = <1>;
			reg = <0 0x14f1f000 0 0x1000>;
			mediatek,gce-client-reg = <&gce1 SUBSYS_14f1XXXX 0xf000 0x1000>;
			interrupts = <GIC_SPI 631 IRQ_TYPE_LEVEL_HIGH 0>;
			clocks = <&vppsys1 CLK_VPP1_SVPP1_MDP_OVL>;
			clock-names = "MDP_OVL1";
			power-domains = <&spm MT8195_POWER_DOMAIN_VPPSYS1>;
		};

		svpp1_mdp3_pad: svpp1_mdp_pad@14f20000 {
			compatible = "mediatek,mt8195-mdp3-pad";
			mediatek,mdp3-id = <1>;
			reg = <0 0x14f20000 0 0x1000>;
			mediatek,gce-client-reg = <&gce1 SUBSYS_14f2XXXX 0 0x1000>;
			interrupts = <GIC_SPI 632 IRQ_TYPE_LEVEL_HIGH 0>;
			clocks = <&vppsys1 CLK_VPP1_SVPP1_VPP_PAD>;
			clock-names = "MDP_PAD1";
			power-domains = <&spm MT8195_POWER_DOMAIN_VPPSYS1>;
		};

		svpp2_mdp3_pad: svpp2_mdp_pad@14f21000 {
			compatible = "mediatek,mt8195-mdp3-pad";
			mediatek,mdp3-id = <2>;
			reg = <0 0x14f21000 0 0x1000>;
			mediatek,gce-client-reg = <&gce1 SUBSYS_14f2XXXX 0x1000 0x1000>;
			interrupts = <GIC_SPI 633 IRQ_TYPE_LEVEL_HIGH 0>;
			clocks = <&vppsys1 CLK_VPP1_SVPP2_VPP_PAD>;
			clock-names = "MDP_PAD2";
			power-domains = <&spm MT8195_POWER_DOMAIN_VPPSYS1>;
		};

		svpp3_mdp3_pad: svpp3_mdp_pad@14f22000 {
			compatible = "mediatek,mt8195-mdp3-pad";
			mediatek,mdp3-id = <3>;
			reg = <0 0x14f22000 0 0x1000>;
			mediatek,gce-client-reg = <&gce1 SUBSYS_14f2XXXX 0x2000 0x1000>;
			interrupts = <GIC_SPI 634 IRQ_TYPE_LEVEL_HIGH 0>;
			clocks = <&vppsys1 CLK_VPP1_SVPP3_VPP_PAD>;
			clock-names = "MDP_PAD3";
			power-domains = <&spm MT8195_POWER_DOMAIN_VPPSYS1>;
		};

		svpp1_mdp3_wrot: svpp1_mdp_wrot@14f23000 {
			compatible = "mediatek,mt8195-mdp3-wrot", "mediatek,mt8183-mdp3-wrot";
			mediatek,mdp3-id = <1>;
			reg = <0 0x14f23000 0 0x1000>;
			mediatek,gce-client-reg = <&gce1 SUBSYS_14f2XXXX 0x3000 0x1000>;
			interrupts = <GIC_SPI 635 IRQ_TYPE_LEVEL_HIGH 0>;
			clocks = <&vppsys1 CLK_VPP1_SVPP1_MDP_WROT>;
			clock-names = "MDP_WROT1";
			iommus = <&iommu_vdo M4U_PORT_L5_SVPP1_MDP_WROT>;
			power-domains = <&spm MT8195_POWER_DOMAIN_VPPSYS1>;
		};

		svpp2_mdp3_wrot: svpp2_mdp_wrot@14f24000 {
			compatible = "mediatek,mt8195-mdp3-wrot", "mediatek,mt8183-mdp3-wrot";
			mediatek,mdp3-id = <2>;
			reg = <0 0x14f24000 0 0x1000>;
			mediatek,gce-client-reg = <&gce1 SUBSYS_14f2XXXX 0x4000 0x1000>;
			interrupts = <GIC_SPI 636 IRQ_TYPE_LEVEL_HIGH 0>;
			clocks = <&vppsys1 CLK_VPP1_SVPP2_MDP_WROT>;
			clock-names = "MDP_WROT2";
			iommus = <&iommu_vdo M4U_PORT_L5_SVPP2_MDP_WROT>;
			power-domains = <&spm MT8195_POWER_DOMAIN_VPPSYS1>;
		};

		svpp3_mdp3_wrot: svpp3_mdp_wrot@14f25000 {
			compatible = "mediatek,mt8195-mdp3-wrot", "mediatek,mt8183-mdp3-wrot";
			mediatek,mdp3-id = <3>;
			reg = <0 0x14f25000 0 0x1000>;
			mediatek,gce-client-reg = <&gce1 SUBSYS_14f2XXXX 0x5000 0x1000>;
			interrupts = <GIC_SPI 637 IRQ_TYPE_LEVEL_HIGH 0>;
			clocks = <&vppsys1 CLK_VPP1_SVPP3_MDP_WROT>;
			clock-names = "MDP_WROT3";
			iommus = <&iommu_vpp M4U_PORT_L6_SVPP3_MDP_WROT>;
			power-domains = <&spm MT8195_POWER_DOMAIN_VPPSYS1>;
		};

		imgsys: clock-controller@15000000 {
			compatible = "mediatek,mt8195-imgsys";
			reg = <0 0x15000000 0 0x1000>;
			#clock-cells = <1>;
		};

		larb9: larb@15001000 {
			compatible = "mediatek,mt8195-smi-larb";
			reg = <0 0x15001000 0 0x1000>;
			mediatek,larb-id = <9>;
			mediatek,smi = <&smi_sub_common_img1_3x1>;
			clocks = <&imgsys CLK_IMG_LARB9>,
			         <&imgsys CLK_IMG_LARB9>,
			         <&imgsys CLK_IMG_GALS>;
			clock-names = "apb", "smi", "gals";
			power-domains = <&spm MT8195_POWER_DOMAIN_IMG>;
		};

		smi_sub_common_img0_3x1: smi@15002000 {
			compatible = "mediatek,mt8195-smi-sub-common";
			reg = <0 0x15002000 0 0x1000>;
			clocks = <&imgsys CLK_IMG_IPE>,
				 <&imgsys CLK_IMG_IPE>,
			         <&vppsys0 CLK_VPP0_GALS_IMGSYS_CAMSYS>;
			clock-names = "apb", "smi", "gals0";
			mediatek,smi = <&smi_common_vpp>;
			mediatek,smi_sub_common;
			power-domains = <&spm MT8195_POWER_DOMAIN_IMG>;
		};

		smi_sub_common_img1_3x1: smi@15003000 {
			compatible = "mediatek,mt8195-smi-sub-common";
			reg = <0 0x15003000 0 0x1000>;
			clocks = <&imgsys CLK_IMG_LARB9>,
				 <&imgsys CLK_IMG_LARB9>,
				 <&imgsys CLK_IMG_GALS>;
			clock-names = "apb", "smi", "gals0";
			mediatek,smi = <&smi_common_vdo>;
			mediatek,smi_sub_common;
			power-domains = <&spm MT8195_POWER_DOMAIN_IMG>;
		};

		imgsys1_dip_top: clock-controller@15110000 {
			compatible = "mediatek,mt8195-imgsys1_dip_top";
			reg = <0 0x15110000 0 0x1000>;
			#clock-cells = <1>;
		};

		larb10: larb@15120000 {
			compatible = "mediatek,mt8195-smi-larb";
			reg = <0 0x15120000 0 0x1000>;
			mediatek,larb-id = <10>;
			mediatek,smi = <&smi_sub_common_img1_3x1>;
			clocks = <&imgsys CLK_IMG_DIP0>,
			       <&imgsys1_dip_top CLK_IMG1_DIP_TOP_LARB10>,
			       <&imgsys CLK_IMG_LARB9>,
			       <&imgsys CLK_IMG_GALS>;
			clock-names = "apb", "smi", "gals", "gals1";
			power-domains = <&spm MT8195_POWER_DOMAIN_DIP>;
		};

		imgsys1_dip_nr: clock-controller@15130000 {
			compatible = "mediatek,mt8195-imgsys1_dip_nr";
			reg = <0 0x15130000 0 0x1000>;
			#clock-cells = <1>;
		};

		imgsys1_wpe: clock-controller@15220000 {
			compatible = "mediatek,mt8195-imgsys1_wpe";
			reg = <0 0x15220000 0 0x1000>;
			#clock-cells = <1>;
		};

		larb11: larb@15230000 {
			compatible = "mediatek,mt8195-smi-larb";
			reg = <0 0x15230000 0 0x1000>;
			mediatek,larb-id = <11>;
			mediatek,smi = <&smi_sub_common_img1_3x1>;
			clocks = <&imgsys CLK_IMG_WPE0>,
			       <&imgsys1_wpe CLK_IMG1_WPE_LARB11>,
			       <&imgsys CLK_IMG_LARB9>,
			       <&imgsys CLK_IMG_GALS>;
			clock-names = "apb", "smi", "gals", "gals1";
			power-domains = <&spm MT8195_POWER_DOMAIN_DIP>;
		};

		ipesys: clock-controller@15330000 {
			compatible = "mediatek,mt8195-ipesys";
			reg = <0 0x15330000 0 0x1000>;
			#clock-cells = <1>;
		};

		larb12: larb@15340000 {
			compatible = "mediatek,mt8195-smi-larb";
			reg = <0 0x15340000 0 0x1000>;
			mediatek,larb-id = <12>;
			mediatek,smi = <&smi_sub_common_img0_3x1>;
			clocks = <&ipesys CLK_IPE_SMI_LARB12>,
				 <&ipesys CLK_IPE_SMI_LARB12>;
			clock-names = "apb", "smi";
			power-domains = <&spm MT8195_POWER_DOMAIN_IPE>;
		};

		camsys: clock-controller@16000000 {
			compatible = "mediatek,mt8195-camsys";
			reg = <0 0x16000000 0 0x1000>;
			#clock-cells = <1>;
		};

		larb13: larb@16001000 {
			compatible = "mediatek,mt8195-smi-larb";
			reg = <0 0x16001000 0 0x1000>;
			mediatek,larb-id = <13>;
			mediatek,smi = <&smi_sub_common_cam_4x1>;
			clocks = <&camsys CLK_CAM_LARB13>,
			       <&camsys CLK_CAM_LARB13>,
			       <&camsys CLK_CAM_CAM2MM0_GALS>;
			clock-names = "apb", "smi", "gals";
			power-domains = <&spm MT8195_POWER_DOMAIN_CAM>;
		};

		larb14: larb@16002000 {
			compatible = "mediatek,mt8195-smi-larb";
			reg = <0 0x16002000 0 0x1000>;
			mediatek,larb-id = <14>;
			mediatek,smi = <&smi_sub_common_cam_7x1>;
			clocks = <&camsys CLK_CAM_LARB14>,
				 <&camsys CLK_CAM_LARB14>;
			clock-names = "apb", "smi";
			power-domains = <&spm MT8195_POWER_DOMAIN_CAM>;
		};

		smi_sub_common_cam_4x1: smi@16004000 {
			compatible = "mediatek,mt8195-smi-sub-common";
			reg = <0 0x16004000 0 0x1000>;
			clocks = <&camsys CLK_CAM_LARB13>,
				 <&camsys CLK_CAM_LARB13>,
				 <&camsys CLK_CAM_CAM2MM0_GALS>;
			clock-names = "apb", "smi", "gals0";
			mediatek,smi = <&smi_common_vdo>;
			mediatek,smi_sub_common;
			power-domains = <&spm MT8195_POWER_DOMAIN_CAM>;
		};

		smi_sub_common_cam_7x1: smi@16005000 {
			compatible = "mediatek,mt8195-smi-sub-common";
			reg = <0 0x16005000 0 0x1000>;
			clocks = <&camsys CLK_CAM_LARB14>,
				 <&camsys CLK_CAM_CAM2MM1_GALS>,
				 <&vppsys0 CLK_VPP0_GALS_IMGSYS_CAMSYS>;
			clock-names = "apb", "smi", "gals0";
			mediatek,smi = <&smi_common_vpp>;
			mediatek,smi_sub_common;
			power-domains = <&spm MT8195_POWER_DOMAIN_CAM>;
		};

		larb16: larb@16012000 {
			compatible = "mediatek,mt8195-smi-larb";
			reg = <0 0x16012000 0 0x1000>;
			mediatek,larb-id = <16>;
			mediatek,smi = <&smi_sub_common_cam_7x1>;
			clocks = <&camsys_rawa CLK_CAM_RAWA_LARBX>,
			         <&camsys_rawa CLK_CAM_RAWA_LARBX>;
			clock-names = "apb", "smi";
			power-domains = <&spm MT8195_POWER_DOMAIN_CAM_RAWA>;
		};

		larb17: larb@16013000 {
			compatible = "mediatek,mt8195-smi-larb";
			reg = <0 0x16013000 0 0x1000>;
			mediatek,larb-id = <17>;
			mediatek,smi = <&smi_sub_common_cam_4x1>;
			clocks = <&camsys_yuva CLK_CAM_YUVA_LARBX>,
			         <&camsys_yuva CLK_CAM_YUVA_LARBX>;
			clock-names = "apb", "smi";
			power-domains = <&spm MT8195_POWER_DOMAIN_CAM_RAWA>;
		};

		larb27: larb@16014000 {
			compatible = "mediatek,mt8195-smi-larb";
			reg = <0 0x16014000 0 0x1000>;
			mediatek,larb-id = <27>;
			mediatek,smi = <&smi_sub_common_cam_7x1>;
			clocks = <&camsys_rawb CLK_CAM_RAWB_LARBX>,
				 <&camsys_rawb CLK_CAM_RAWB_LARBX>;
			clock-names = "apb", "smi";
			power-domains = <&spm MT8195_POWER_DOMAIN_CAM_RAWB>;
		};

		larb28: larb@16015000 {
			compatible = "mediatek,mt8195-smi-larb";
			reg = <0 0x16015000 0 0x1000>;
			mediatek,larb-id = <28>;
			mediatek,smi = <&smi_sub_common_cam_4x1>;
			clocks = <&camsys_yuvb CLK_CAM_YUVB_LARBX>,
				 <&camsys_yuvb CLK_CAM_YUVB_LARBX>;
			clock-names = "apb", "smi";
			power-domains = <&spm MT8195_POWER_DOMAIN_CAM_RAWB>;
		};

		camsys_rawa: clock-controller@1604f000 {
			compatible = "mediatek,mt8195-camsys_rawa";
			reg = <0 0x1604f000 0 0x1000>;
			#clock-cells = <1>;
		};

		camsys_yuva: clock-controller@1606f000 {
			compatible = "mediatek,mt8195-camsys_yuva";
			reg = <0 0x1606f000 0 0x1000>;
			#clock-cells = <1>;
		};

		camsys_rawb: clock-controller@1608f000 {
			compatible = "mediatek,mt8195-camsys_rawb";
			reg = <0 0x1608f000 0 0x1000>;
			#clock-cells = <1>;
		};

		camsys_yuvb: clock-controller@160af000 {
			compatible = "mediatek,mt8195-camsys_yuvb";
			reg = <0 0x160af000 0 0x1000>;
			#clock-cells = <1>;
		};

		camsys_mraw: clock-controller@16140000 {
			compatible = "mediatek,mt8195-camsys_mraw";
			reg = <0 0x16140000 0 0x1000>;
			#clock-cells = <1>;
		};

		larb25: larb@16141000 {
			compatible = "mediatek,mt8195-smi-larb";
			reg = <0 0x16141000 0 0x1000>;
			mediatek,larb-id = <25>;
			mediatek,smi = <&smi_sub_common_cam_4x1>;
			clocks = <&camsys CLK_CAM_LARB13>,
			         <&camsys_mraw CLK_CAM_MRAW_LARBX>,
			         <&camsys CLK_CAM_CAM2MM0_GALS>;
			clock-names = "apb", "smi", "gals";
			power-domains = <&spm MT8195_POWER_DOMAIN_CAM_MRAW>;
		};

		larb26: larb@16142000 {
			compatible = "mediatek,mt8195-smi-larb";
			reg = <0 0x16142000 0 0x1000>;
			mediatek,larb-id = <26>;
			mediatek,smi = <&smi_sub_common_cam_7x1>;
			clocks = <&camsys_mraw CLK_CAM_MRAW_LARBX>,
				 <&camsys_mraw CLK_CAM_MRAW_LARBX>;
			clock-names = "apb", "smi";
			power-domains = <&spm MT8195_POWER_DOMAIN_CAM_MRAW>;

		};

		ccusys: clock-controller@17200000 {
			compatible = "mediatek,mt8195-ccusys";
			reg = <0 0x17200000 0 0x1000>;
			#clock-cells = <1>;
		};

		larb18: larb@17201000 {
			compatible = "mediatek,mt8195-smi-larb";
			reg = <0 0x17201000 0 0x1000>;
			mediatek,larb-id = <18>;
			mediatek,smi = <&smi_sub_common_cam_7x1>;
			clocks = <&ccusys CLK_CCU_LARB18>,
				 <&ccusys CLK_CCU_LARB18>;
			clock-names = "apb", "smi";
			power-domains = <&spm MT8195_POWER_DOMAIN_CAM>;
		};

		vcodec_dec: vcodec_dec@18000000 {
			compatible = "mediatek,mt8195-vcodec-dec";
			reg = <0 0x18000000 0 0x1000>;		/* VDEC_SYS */
			mediatek,scp = <&scp>;
			iommus = <&iommu_vdo M4U_PORT_L21_VDEC_MC_EXT>;
			dma-ranges = <0x1 0x0 0x0 0x40000000 0x0 0xfff00000>;
		};

		vcodec_lat_soc: vcodec_lat_soc@0x18002000 {
			compatible = "mediatek,mtk-vcodec-lat-soc";
			reg = <0 0x18002000 0 0x800>;		/* VDEC_MISC */
			iommus = <&iommu_vpp M4U_PORT_L23_VDEC_UFO_ENC_EXT>,
				<&iommu_vpp M4U_PORT_L23_VDEC_RDMA_EXT>;
			clocks = <&topckgen CLK_TOP_VDEC>,
				<&vdecsys_soc CLK_VDEC_SOC_VDEC>,
				 <&vdecsys_soc CLK_VDEC_SOC_LAT>,
				 <&topckgen CLK_TOP_UNIVPLL_D4>;
			clock-names = "vdec-sel", "vdec-soc-vdec", "vdec-soc-lat", "vdec-top";
				 assigned-clocks = <&topckgen CLK_TOP_VDEC>;
			assigned-clock-parents = <&topckgen CLK_TOP_UNIVPLL_D4>;
			power-domains = <&spm MT8195_POWER_DOMAIN_VDEC0>;
			dma-ranges = <0x1 0x0 0x0 0x40000000 0x0 0xfff00000>;
		};

		vcodec_lat: vcodec_lat@0x18010000 {
			compatible = "mediatek,mtk-vcodec-lat";
			reg = <0 0x18010000 0 0x800>;		/* VDEC_MISC */
			interrupts = <GIC_SPI 708 IRQ_TYPE_LEVEL_HIGH 0>;
			iommus = <&iommu_vdo M4U_PORT_L24_VDEC_LAT0_VLD_EXT>,
				<&iommu_vdo M4U_PORT_L24_VDEC_LAT0_VLD2_EXT>,
				<&iommu_vdo M4U_PORT_L24_VDEC_LAT0_AVC_MC_EXT>,
				<&iommu_vdo M4U_PORT_L24_VDEC_LAT0_PRED_RD_EXT>,
				<&iommu_vdo M4U_PORT_L24_VDEC_LAT0_TILE_EXT>,
				<&iommu_vdo M4U_PORT_L24_VDEC_LAT0_WDMA_EXT>;
			clocks = <&topckgen CLK_TOP_VDEC>,
				 <&vdecsys_soc CLK_VDEC_SOC_VDEC>,
				 <&vdecsys_soc CLK_VDEC_SOC_LAT>,
				 <&topckgen CLK_TOP_UNIVPLL_D4>;
			clock-names = "vdec-sel", "vdec-soc-vdec", "vdec-soc-lat", "vdec-top";
			assigned-clocks = <&topckgen CLK_TOP_VDEC>;
			assigned-clock-parents = <&topckgen CLK_TOP_UNIVPLL_D4>;
			power-domains =  <&spm MT8195_POWER_DOMAIN_VDEC0>;
			dma-ranges = <0x1 0x0 0x0 0x40000000 0x0 0xfff00000>;
		};

		vcodec_core: vcodec_core@0x18025000 {
			compatible = "mediatek,mtk-vcodec-core";
			reg = <0 0x18025000 0 0x1000>;		/* VDEC_CORE_MISC */
			interrupts = <GIC_SPI 707 IRQ_TYPE_LEVEL_HIGH 0>;
			iommus = <&iommu_vdo M4U_PORT_L21_VDEC_MC_EXT>,
				<&iommu_vdo M4U_PORT_L21_VDEC_UFO_EXT>,
				<&iommu_vdo M4U_PORT_L21_VDEC_PP_EXT>,
				<&iommu_vdo M4U_PORT_L21_VDEC_PRED_RD_EXT>,
				<&iommu_vdo M4U_PORT_L21_VDEC_PRED_WR_EXT>,
				<&iommu_vdo M4U_PORT_L21_VDEC_PPWRAP_EXT>,
				<&iommu_vdo M4U_PORT_L21_VDEC_TILE_EXT>,
				<&iommu_vdo M4U_PORT_L21_VDEC_VLD_EXT>,
				<&iommu_vdo M4U_PORT_L21_VDEC_VLD2_EXT>,
				<&iommu_vdo M4U_PORT_L21_VDEC_AVC_MV_EXT>;
			clocks = <&topckgen CLK_TOP_VDEC>,
				 <&vdecsys CLK_VDEC_VDEC>,
				 <&vdecsys CLK_VDEC_LAT>,
				 <&topckgen CLK_TOP_UNIVPLL_D4>;
			clock-names = "vdec-sel", "vdec-soc-vdec", "vdec-soc-lat", "vdec-top";
			assigned-clocks = <&topckgen CLK_TOP_VDEC>;
			assigned-clock-parents = <&topckgen CLK_TOP_UNIVPLL_D4>;
			power-domains = <&spm MT8195_POWER_DOMAIN_VDEC1>;
			dma-ranges = <0x1 0x0 0x0 0x40000000 0x0 0xfff00000>;
		};

		vcodec_core1: vcodec_core1@0x18035000 {
			compatible = "mediatek,mtk-vcodec-core1";
			reg = <0 0x18035000 0 0x1000>;		/* VDEC_CORE1_MISC */
			interrupts = <GIC_SPI 709 IRQ_TYPE_LEVEL_HIGH 0>;
			iommus = <&iommu_vpp M4U_PORT_L22_VDEC_MC_EXT>,
				<&iommu_vpp M4U_PORT_L22_VDEC_UFO_EXT>,
				<&iommu_vpp M4U_PORT_L22_VDEC_PP_EXT>,
				<&iommu_vpp M4U_PORT_L22_VDEC_PRED_RD_EXT>,
				<&iommu_vpp M4U_PORT_L22_VDEC_PRED_WR_EXT>,
				<&iommu_vpp M4U_PORT_L22_VDEC_PPWRAP_EXT>,
				<&iommu_vpp M4U_PORT_L22_VDEC_TILE_EXT>,
				<&iommu_vpp M4U_PORT_L22_VDEC_VLD_EXT>,
				<&iommu_vpp M4U_PORT_L22_VDEC_VLD2_EXT>,
				<&iommu_vpp M4U_PORT_L22_VDEC_AVC_MV_EXT>;
			clocks = <&topckgen CLK_TOP_VDEC>,
				 <&vdecsys CLK_VDEC_CORE1_VDEC>,
				 <&vdecsys CLK_VDEC_CORE1_LAT>,
				 <&topckgen CLK_TOP_UNIVPLL_D4>;
			clock-names = "vdec-sel", "vdec-soc-vdec", "vdec-soc-lat", "vdec-top";
			assigned-clocks = <&topckgen CLK_TOP_VDEC>;
			assigned-clock-parents = <&topckgen CLK_TOP_UNIVPLL_D4>;
			power-domains = <&spm MT8195_POWER_DOMAIN_VDEC2>;
			dma-ranges = <0x1 0x0 0x0 0x40000000 0x0 0xfff00000>;
		};

		larb24: larb@1800d000 {
			compatible = "mediatek,mt8195-smi-larb";
			reg = <0 0x1800d000 0 0x1000>;
			mediatek,larb-id = <24>;
			mediatek,smi = <&smi_common_vdo>;
			clocks = <&vdecsys_soc CLK_VDEC_SOC_LARB1>,
			         <&vdecsys_soc CLK_VDEC_SOC_LARB1>;
			clock-names = "apb", "smi";
			power-domains = <&spm MT8195_POWER_DOMAIN_VDEC0>;
		};

		larb23: larb@1800e000 {
			compatible = "mediatek,mt8195-smi-larb";
			reg = <0 0x1800e000 0 0x1000>;
			mediatek,larb-id = <23>;
			mediatek,smi = <&smi_sub_common_vdec_vpp0_2x1>;
			clocks = <&vppsys0 CLK_VPP0_GALS_VDEC_VDEC_CORE1>,
			         <&vdecsys_soc CLK_VDEC_SOC_LARB1>;
			clock-names = "apb", "smi";
			power-domains = <&spm MT8195_POWER_DOMAIN_VDEC0>;
		};

		vdecsys_soc: clock-controller@1800f000 {
			compatible = "mediatek,mt8195-vdecsys_soc";
			reg = <0 0x1800f000 0 0x1000>;
			#clock-cells = <1>;
		};

		larb21: larb@1802e000 {
			compatible = "mediatek,mt8195-smi-larb";
			reg = <0 0x1802e000 0 0x1000>;
			mediatek,larb-id = <21>;
			mediatek,smi = <&smi_common_vdo>;
			clocks = <&vdecsys CLK_VDEC_LARB1>,
			       <&vdecsys CLK_VDEC_LARB1>;
			clock-names = "apb", "smi";
			power-domains = <&spm MT8195_POWER_DOMAIN_VDEC1>;
		};

		vdecsys: clock-controller@1802f000 {
			compatible = "mediatek,mt8195-vdecsys";
			reg = <0 0x1802f000 0 0x1000>;
			#clock-cells = <1>;
		};

		larb22: larb@1803e000 {
			compatible = "mediatek,mt8195-smi-larb";
			reg = <0 0x1803e000 0 0x1000>;
			mediatek,larb-id = <22>;
			mediatek,smi = <&smi_sub_common_vdec_vpp0_2x1>;
			clocks = <&vppsys0 CLK_VPP0_GALS_VDEC_VDEC_CORE1>,
			         <&vdecsys_core1 CLK_VDEC_CORE1_LARB1>;
			clock-names = "apb", "smi";
			power-domains = <&spm MT8195_POWER_DOMAIN_VDEC2>;
		};

		vdecsys_core1: clock-controller@1803f000 {
			compatible = "mediatek,mt8195-vdecsys_core1";
			reg = <0 0x1803f000 0 0x1000>;
			#clock-cells = <1>;
		};

		iommu_apu0: iommu@19010000 {
			compatible = "mediatek,mt8195-iommu-apu";
			reg = <0 0x19010000 0 0x1000>;
			interrupts = <GIC_SPI 426 IRQ_TYPE_LEVEL_HIGH 0>;
			clocks = <&clk26m>;
			clock-names = "bclk";
			#iommu-cells = <1>;
			/* power-domains = <&apuspm MT8195_POWER_DOMAIN_APUSYS_TOP>; */
			status = "disabled";
		};

		iommu_apu1: iommu@19015000 {
			compatible = "mediatek,mt8195-iommu-apu";
			reg = <0 0x19015000 0 0x1000>;
			interrupts = <GIC_SPI 431 IRQ_TYPE_LEVEL_HIGH 0>;
			clocks = <&clk26m>;
			clock-names = "bclk";
			#iommu-cells = <1>;
			/* power-domains = <&apuspm MT8195_POWER_DOMAIN_APUSYS_TOP>; */
			status = "disabled";
		};

		apusys_pll: clock-controller@190f3000 {
			compatible = "mediatek,mt8195-apusys_pll";
			reg = <0 0x190f3000 0 0x1000>;
			#clock-cells = <1>;
		};

		vencsys: clock-controller@1a000000 {
			compatible = "mediatek,mt8195-vencsys";
			reg = <0 0x1a000000 0 0x1000>;
			#clock-cells = <1>;
		};

		larb19: larb@1a010000 {
			compatible = "mediatek,mt8195-smi-larb";
			reg = <0 0x1a010000 0 0x1000>;
			mediatek,larb-id = <19>;
			mediatek,smi = <&smi_common_vdo>;
			clocks = <&vencsys CLK_VENC_VENC>,
				 <&vencsys CLK_VENC_GALS>;
			clock-names = "apb", "smi";
			power-domains = <&spm MT8195_POWER_DOMAIN_VENC>;
		};

		venc: venc@1a020000 {
			compatible = "mediatek,mt8195-vcodec-enc";
			reg = <0 0x1a020000 0 0x10000>;/* VENC_C0 */
			iommus = <&iommu_vdo M4U_PORT_L19_VENC_RCPU>,
					<&iommu_vdo M4U_PORT_L19_VENC_REC>,
					<&iommu_vdo M4U_PORT_L19_VENC_BSDMA>,
					<&iommu_vdo M4U_PORT_L19_VENC_SV_COMV>,
					<&iommu_vdo M4U_PORT_L19_VENC_RD_COMV>,
					<&iommu_vdo M4U_PORT_L19_VENC_CUR_LUMA>,
					<&iommu_vdo M4U_PORT_L19_VENC_CUR_CHROMA>,
					<&iommu_vdo M4U_PORT_L19_VENC_REF_LUMA>,
					<&iommu_vdo M4U_PORT_L19_VENC_REF_CHROMA>;
			interrupts = <GIC_SPI 341 IRQ_TYPE_LEVEL_HIGH 0>;
			mediatek,scp = <&scp>;
			clocks = <&vencsys CLK_VENC_VENC>;
			clock-names = "MT_CG_VENC0";
			assigned-clocks = <&topckgen CLK_TOP_VENC>;
			assigned-clock-parents = <&topckgen CLK_TOP_UNIVPLL_D4>;
			power-domains = <&spm MT8195_POWER_DOMAIN_VENC>;
			dma-ranges = <0x1 0x0 0x0 0x40000000 0x0 0xfff00000>;
		};

		vencsys_core1: clock-controller@1b000000 {
			compatible = "mediatek,mt8195-vencsys_core1";
			reg = <0 0x1b000000 0 0x1000>;
			#clock-cells = <1>;
		};

		larb20: larb@1b010000 {
			compatible = "mediatek,mt8195-smi-larb";
			reg = <0 0x1b010000 0 0x1000>;
			mediatek,larb-id = <20>;
			mediatek,smi = <&smi_common_vpp>;
			clocks = <&vencsys_core1 CLK_VENC_CORE1_LARB>,
				 <&vencsys_core1 CLK_VENC_CORE1_GALS>,
				 <&vppsys0 CLK_VPP0_GALS_VDO0_VDO1_VENCSYS_CORE1>;
			clock-names = "apb", "smi", "gals";
			power-domains = <&spm MT8195_POWER_DOMAIN_VENC_CORE1>;
		};

		ovl0: disp_ovl@1c000000 {
			compatible = "mediatek,mt8195-disp-ovl",
				     "mediatek,mt8192-disp-ovl";
			reg = <0 0x1c000000 0 0x1000>;
			interrupts = <GIC_SPI 636 IRQ_TYPE_LEVEL_HIGH 0>;
			power-domains = <&spm MT8195_POWER_DOMAIN_VDOSYS0>;
			clocks = <&vdosys0 CLK_VDO0_DISP_OVL0>;
			iommus = <&iommu_vdo M4U_PORT_L0_DISP_OVL0_RDMA0>;
			mediatek,gce-client-reg =
				 <&gce0 SUBSYS_1c00XXXX 0x0000 0x1000>;
		};

		rdma0: disp_rdma@1c002000 {
			compatible = "mediatek,mt8195-disp-rdma";
			reg = <0 0x1c002000 0 0x1000>;
			interrupts = <GIC_SPI 638 IRQ_TYPE_LEVEL_HIGH 0>;
			power-domains = <&spm MT8195_POWER_DOMAIN_VDOSYS0>;
			clocks = <&vdosys0 CLK_VDO0_DISP_RDMA0>;
			iommus = <&iommu_vdo M4U_PORT_L0_DISP_RDMA0>;
			mediatek,gce-client-reg =
				 <&gce0 SUBSYS_1c00XXXX 0x2000 0x1000>;
		};

		color0: disp_color@1c003000 {
			compatible = "mediatek,mt8195-disp-color",
				     "mediatek,mt8173-disp-color";
			reg = <0 0x1c003000 0 0x1000>;
			interrupts = <GIC_SPI 639 IRQ_TYPE_LEVEL_HIGH 0>;
			power-domains = <&spm MT8195_POWER_DOMAIN_VDOSYS0>;
			clocks = <&vdosys0 CLK_VDO0_DISP_COLOR0>;
			mediatek,gce-client-reg =
				 <&gce0 SUBSYS_1c00XXXX 0x3000 0x1000>;
		};

		ccorr0: disp_ccorr@1c004000 {
			compatible = "mediatek,mt8192-disp-ccorr";
			reg = <0 0x1c004000 0 0x1000>;
			interrupts = <GIC_SPI 640 IRQ_TYPE_LEVEL_HIGH 0>;
			power-domains = <&spm MT8195_POWER_DOMAIN_VDOSYS0>;
			clocks = <&vdosys0 CLK_VDO0_DISP_CCORR0>;
			mediatek,gce-client-reg =
				 <&gce0 SUBSYS_1c00XXXX 0x4000 0x1000>;
		};

		aal0: disp_aal@1c005000 {
			compatible = "mediatek,mt8195-disp-aal",
				     "mediatek,mt8173-disp-aal";
			reg = <0 0x1c005000 0 0x1000>;
			interrupts = <GIC_SPI 641 IRQ_TYPE_LEVEL_HIGH 0>;
			power-domains = <&spm MT8195_POWER_DOMAIN_VDOSYS0>;
			clocks = <&vdosys0 CLK_VDO0_DISP_AAL0>;
			mediatek,gce-client-reg =
				 <&gce0 SUBSYS_1c00XXXX 0x5000 0x1000>;
		};

		gamma0: disp_gamma@1c006000 {
			compatible = "mediatek,mt8195-disp-gamma",
				     "mediatek,mt8173-disp-gamma";
			reg = <0 0x1c006000 0 0x1000>;
			interrupts = <GIC_SPI 642 IRQ_TYPE_LEVEL_HIGH 0>;
			power-domains = <&spm MT8195_POWER_DOMAIN_VDOSYS0>;
			clocks = <&vdosys0 CLK_VDO0_DISP_GAMMA0>;
			mediatek,gce-client-reg =
				 <&gce0 SUBSYS_1c00XXXX 0x6000 0x1000>;
		};

		dither0: disp_dither@1c007000 {
			compatible = "mediatek,mt8195-disp-dither",
				     "mediatek,mt8183-disp-dither";
			reg = <0 0x1c007000 0 0x1000>;
			interrupts = <GIC_SPI 643 IRQ_TYPE_LEVEL_HIGH 0>;
			power-domains = <&spm MT8195_POWER_DOMAIN_VDOSYS0>;
			clocks = <&vdosys0 CLK_VDO0_DISP_DITHER0>;
			mediatek,gce-client-reg =
				 <&gce0 SUBSYS_1c00XXXX 0x7000 0x1000>;
		};

		dsc0: disp_dsc_wrap@1c009000 {
			compatible = "mediatek,mt8195-disp-dsc";
			reg = <0 0x1c009000 0 0x1000>;
			interrupts = <GIC_SPI 645 IRQ_TYPE_LEVEL_HIGH 0>;
			power-domains = <&spm MT8195_POWER_DOMAIN_VDOSYS0>;
			clocks = <&vdosys0 CLK_VDO0_DSC_WRAP0>;
			mediatek,gce-client-reg =
				 <&gce0 SUBSYS_1c00XXXX 0x9000 0x1000>;
		};

		merge0: disp_vpp_merge0@1c014000 {
			compatible = "mediatek,mt8195-disp-merge";
			reg = <0 0x1c014000 0 0x1000>;
			interrupts = <GIC_SPI 656 IRQ_TYPE_LEVEL_HIGH 0>;
			power-domains = <&spm MT8195_POWER_DOMAIN_VDOSYS0>;
			clocks = <&vdosys0 CLK_VDO0_VPP_MERGE0>;
			mediatek,gce-client-reg =
				 <&gce0 SUBSYS_1c01XXXX 0x4000 0x1000>;
		};

		dp_intf0: dp_intf0@1c015000 {
			status = "disabled";
			compatible = "mediatek,mt8195-dpintf";
			reg = <0 0x1c015000 0 0x1000>;
			interrupts = <GIC_SPI 657 IRQ_TYPE_LEVEL_HIGH 0>;
			clocks = <&vdosys0  CLK_VDO0_DP_INTF0>,
				<&vdosys0 CLK_VDO0_DP_INTF0_DP_INTF>,
				<&topckgen CLK_TOP_EDP>,
				<&apmixedsys CLK_APMIXED_TVDPLL1>,
				<&topckgen CLK_TOP_TVDPLL1_D2>,
				<&topckgen CLK_TOP_TVDPLL1_D4>,
				<&topckgen CLK_TOP_TVDPLL1_D8>,
				<&topckgen CLK_TOP_TVDPLL1_D16>;
			clock-names = "engine",
				      "ck_cg",
				      "pixel",
				      "pll",
				      "TVDPLL_D2",
				      "TVDPLL_D4",
				      "TVDPLL_D8",
				      "TVDPLL_D16";
		};

		mutex: disp_mutex0@1c016000 {
			compatible = "mediatek,mt8195-disp-mutex";
			reg = <0 0x1c016000 0 0x1000>;
			reg-names = "vdo0_mutex";
			interrupts = <GIC_SPI 658 IRQ_TYPE_LEVEL_HIGH 0>;
			power-domains = <&spm MT8195_POWER_DOMAIN_VDOSYS0>;
			clocks = <&vdosys0 CLK_VDO0_DISP_MUTEX0>;
			clock-names = "vdo0_mutex";
			mediatek,gce-events =
				 <CMDQ_EVENT_VDO0_DISP_STREAM_DONE_0>;
		};

		larb0: larb@1c018000 {
			compatible = "mediatek,mt8195-smi-larb";
			reg = <0 0x1c018000 0 0x1000>;
			mediatek,larb-id = <0>;
			mediatek,smi = <&smi_common_vdo>;
			clocks = <&vdosys0 CLK_VDO0_SMI_LARB>,
				 <&vdosys0 CLK_VDO0_SMI_LARB>,
				 <&vppsys0 CLK_VPP0_GALS_VDO0_LARB0>;
			clock-names = "apb", "smi", "gals";
			power-domains = <&spm MT8195_POWER_DOMAIN_VDOSYS0>;
		};

		larb1: larb@1c019000 {
			compatible = "mediatek,mt8195-smi-larb";
			reg = <0 0x1c019000 0 0x1000>;
			mediatek,larb-id = <1>;
			mediatek,smi = <&smi_common_vpp>;
			clocks = <&vdosys0 CLK_VDO0_SMI_LARB>,
				 <&vppsys0 CLK_VPP0_GALS_VDO0_VDO1_VENCSYS_CORE1>,
				 <&vppsys0 CLK_VPP0_GALS_VDO0_LARB1>;
			clock-names = "apb", "smi", "gals";
			power-domains = <&spm MT8195_POWER_DOMAIN_VDOSYS0>;
		};

		vdosys0: clock-controller@1c01a000 {
			compatible = "mediatek,mt8195-vdosys0";
			reg = <0 0x1c01a000 0 0x1000>;
			mboxes = <&gce0 0 CMDQ_THR_PRIO_4>;
			#clock-cells = <1>;
		};

		smi_common_vdo: smi@1c01b000 {
			compatible = "mediatek,mt8195-smi-common-vdo";
			reg = <0 0x1c01b000 0 0x1000>;
			clocks = <&vdosys0 CLK_VDO0_SMI_COMMON>,
				 <&vdosys0 CLK_VDO0_SMI_EMI>,
				 <&vdosys0 CLK_VDO0_SMI_RSI>,
				 <&vdosys0 CLK_VDO0_SMI_GALS>;
			clock-names = "apb", "smi", "gals0", "gals1";
			power-domains = <&spm MT8195_POWER_DOMAIN_VDOSYS0>;

		};

		iommu_vdo: iommu@1c01f000 {
			compatible = "mediatek,mt8195-iommu-vdo";
			reg = <0 0x1c01f000 0 0x1000>;
			mediatek,larbs = <&larb0 &larb2 &larb5 &larb7 &larb9
					  &larb10 &larb11 &larb13 &larb17
					  &larb19 &larb21 &larb24 &larb25
					  &larb28>;
			interrupts = <GIC_SPI 669 IRQ_TYPE_LEVEL_HIGH 0>;
			#iommu-cells = <1>;
			clocks = <&vdosys0 CLK_VDO0_SMI_IOMMU>;
			clock-names = "bclk";
			power-domains = <&spm MT8195_POWER_DOMAIN_VDOSYS0>;
		};

		vdosys1: clock-controller@1c100000 {
			compatible = "mediatek,mt8195-vdosys1";
			reg = <0 0x1c100000 0 0x1000>;
			mboxes = <&gce0 1 CMDQ_THR_PRIO_4>;
			mediatek,gce-client-reg = <&gce0 SUBSYS_1c10XXXX 0x0000 0x1000>;
			#clock-cells = <1>;
			#reset-cells = <1>;
		};

		mutex1: disp_mutex0@1c101000 {
			compatible = "mediatek,mt8195-disp-mutex";
			reg = <0 0x1c101000 0 0x1000>;
			reg-names = "vdo1_mutex";
			interrupts = <GIC_SPI 494 IRQ_TYPE_LEVEL_HIGH 0>;
			power-domains = <&spm MT8195_POWER_DOMAIN_VDOSYS1>;
			clocks = <&vdosys1 CLK_VDO1_DISP_MUTEX>;
			clock-names = "vdo1_mutex";
			mediatek,gce-events = <CMDQ_EVENT_VDO1_STREAM_DONE_ENG_0>;
		};

		larb2: larb@1c102000 {
			compatible = "mediatek,mt8195-smi-larb";
			reg = <0 0x1c102000 0 0x1000>;
			mediatek,larb-id = <2>;
			mediatek,smi = <&smi_common_vdo>;
			clocks = <&vdosys1 CLK_VDO1_SMI_LARB2>,
			         <&vdosys1 CLK_VDO1_SMI_LARB2>,
			         <&vdosys1 CLK_VDO1_GALS>;
			clock-names = "apb", "smi", "gals";
			power-domains = <&spm MT8195_POWER_DOMAIN_VDOSYS1>;
		};

		larb3: larb@1c103000 {
			compatible = "mediatek,mt8195-smi-larb";
			reg = <0 0x1c103000 0 0x1000>;
			mediatek,larb-id = <3>;
			mediatek,smi = <&smi_common_vpp>;
			clocks = <&vdosys1 CLK_VDO1_SMI_LARB3>,
			         <&vdosys1 CLK_VDO1_GALS>,
			         <&vppsys0 CLK_VPP0_GALS_VDO0_VDO1_VENCSYS_CORE1>;
			clock-names = "apb", "smi", "gals";
			power-domains = <&spm MT8195_POWER_DOMAIN_VDOSYS1>;
		};

		vdo1_rdma0: vdo1_rdma@1c104000 {
			compatible = "mediatek,mt8195-vdo1-rdma";
			reg = <0 0x1c104000 0 0x1000>;
			interrupts = <GIC_SPI 495 IRQ_TYPE_LEVEL_HIGH 0>;
			clocks = <&vdosys1 CLK_VDO1_MDP_RDMA0>;
			power-domains = <&spm MT8195_POWER_DOMAIN_VDOSYS1>;
			iommus = <&iommu_vdo M4U_PORT_L2_MDP_RDMA0>;
			mediatek,gce-client-reg = <&gce0 SUBSYS_1c10XXXX 0x4000 0x1000>;
		};

		vdo1_rdma1: vdo1_rdma@1c105000 {
			compatible = "mediatek,mt8195-vdo1-rdma";
			reg = <0 0x1c105000 0 0x1000>;
			interrupts = <GIC_SPI 496 IRQ_TYPE_LEVEL_HIGH 0>;
			clocks = <&vdosys1 CLK_VDO1_MDP_RDMA1>;
			power-domains = <&spm MT8195_POWER_DOMAIN_VDOSYS1>;
			iommus = <&iommu_vpp M4U_PORT_L3_MDP_RDMA1>;
			mediatek,gce-client-reg = <&gce0 SUBSYS_1c10XXXX 0x5000 0x1000>;
		};

		vdo1_rdma2: vdo1_rdma@1c106000 {
			compatible = "mediatek,mt8195-vdo1-rdma";
			reg = <0 0x1c106000 0 0x1000>;
			interrupts = <GIC_SPI 497 IRQ_TYPE_LEVEL_HIGH 0>;
			clocks = <&vdosys1 CLK_VDO1_MDP_RDMA2>;
			power-domains = <&spm MT8195_POWER_DOMAIN_VDOSYS1>;
			iommus = <&iommu_vdo M4U_PORT_L2_MDP_RDMA2>;
			mediatek,gce-client-reg = <&gce0 SUBSYS_1c10XXXX 0x6000 0x1000>;
		};

		vdo1_rdma3: vdo1_rdma@1c107000 {
			compatible = "mediatek,mt8195-vdo1-rdma";
			reg = <0 0x1c107000 0 0x1000>;
			interrupts = <GIC_SPI 498 IRQ_TYPE_LEVEL_HIGH 0>;
			clocks = <&vdosys1 CLK_VDO1_MDP_RDMA3>;
			power-domains = <&spm MT8195_POWER_DOMAIN_VDOSYS1>;
			iommus = <&iommu_vpp M4U_PORT_L3_MDP_RDMA3>;
			mediatek,gce-client-reg = <&gce0 SUBSYS_1c10XXXX 0x7000 0x1000>;
		};

		vdo1_rdma4: vdo1_rdma@1c108000 {
			compatible = "mediatek,mt8195-vdo1-rdma";
			reg = <0 0x1c108000 0 0x1000>;
			interrupts = <GIC_SPI 499 IRQ_TYPE_LEVEL_HIGH 0>;
			clocks = <&vdosys1 CLK_VDO1_MDP_RDMA4>;
			power-domains = <&spm MT8195_POWER_DOMAIN_VDOSYS1>;
			iommus = <&iommu_vdo M4U_PORT_L2_MDP_RDMA4>;
			mediatek,gce-client-reg = <&gce0 SUBSYS_1c10XXXX 0x8000 0x1000>;
		};

		vdo1_rdma5: vdo1_rdma@1c109000 {
			compatible = "mediatek,mt8195-vdo1-rdma";
			reg = <0 0x1c109000 0 0x1000>;
			interrupts = <GIC_SPI 500 IRQ_TYPE_LEVEL_HIGH 0>;
			clocks = <&vdosys1 CLK_VDO1_MDP_RDMA5>;
			power-domains = <&spm MT8195_POWER_DOMAIN_VDOSYS1>;
			iommus = <&iommu_vpp M4U_PORT_L3_MDP_RDMA5>;
			mediatek,gce-client-reg = <&gce0 SUBSYS_1c10XXXX 0x9000 0x1000>;
		};

		vdo1_rdma6: vdo1_rdma@1c10a000 {
			compatible = "mediatek,mt8195-vdo1-rdma";
			reg = <0 0x1c10a000 0 0x1000>;
			interrupts = <GIC_SPI 501 IRQ_TYPE_LEVEL_HIGH 0>;
			clocks = <&vdosys1 CLK_VDO1_MDP_RDMA6>;
			power-domains = <&spm MT8195_POWER_DOMAIN_VDOSYS1>;
			iommus = <&iommu_vdo M4U_PORT_L2_MDP_RDMA6>;
			mediatek,gce-client-reg = <&gce0 SUBSYS_1c10XXXX 0xa000 0x1000>;
		};

		vdo1_rdma7: vdo1_rdma@1c10b000 {
			compatible = "mediatek,mt8195-vdo1-rdma";
			reg = <0 0x1c10b000 0 0x1000>;
			interrupts = <GIC_SPI 502 IRQ_TYPE_LEVEL_HIGH 0>;
			clocks = <&vdosys1 CLK_VDO1_MDP_RDMA7>;
			power-domains = <&spm MT8195_POWER_DOMAIN_VDOSYS1>;
			iommus = <&iommu_vpp M4U_PORT_L3_MDP_RDMA7>;
			mediatek,gce-client-reg = <&gce0 SUBSYS_1c10XXXX 0xb000 0x1000>;
		};

		merge1: disp_vpp_merge@1c10c000 {
			compatible = "mediatek,mt8195-disp-merge";
			reg = <0 0x1c10c000 0 0x1000>;
			interrupts = <GIC_SPI 503 IRQ_TYPE_LEVEL_HIGH 0>;
			clocks = <&vdosys1 CLK_VDO1_VPP_MERGE0>,
				 <&vdosys1 CLK_VDO1_MERGE0_DL_ASYNC>;
			clock-names = "merge","merge_async";
			power-domains = <&spm MT8195_POWER_DOMAIN_VDOSYS1>;
			mediatek,gce-client-reg = <&gce0 SUBSYS_1c10XXXX 0xc000 0x1000>;
			mediatek,merge-mute = <1>;
			resets = <&vdosys1 MT8195_VDOSYS1_SW0_RST_B_MERGE0_DL_ASYNC>;
		};

		merge2: disp_vpp_merge@1c10d000 {
			compatible = "mediatek,mt8195-disp-merge";
			reg = <0 0x1c10d000 0 0x1000>;
			interrupts = <GIC_SPI 504 IRQ_TYPE_LEVEL_HIGH 0>;
			clocks = <&vdosys1 CLK_VDO1_VPP_MERGE1>,
				 <&vdosys1 CLK_VDO1_MERGE1_DL_ASYNC>;
			clock-names = "merge","merge_async";
			power-domains = <&spm MT8195_POWER_DOMAIN_VDOSYS1>;
			mediatek,gce-client-reg = <&gce0 SUBSYS_1c10XXXX 0xd000 0x1000>;
			mediatek,merge-mute = <1>;
			resets = <&vdosys1 MT8195_VDOSYS1_SW0_RST_B_MERGE1_DL_ASYNC>;
		};

		merge3: disp_vpp_merge@1c10e000 {
			compatible = "mediatek,mt8195-disp-merge";
			reg = <0 0x1c10e000 0 0x1000>;
			interrupts = <GIC_SPI 505 IRQ_TYPE_LEVEL_HIGH 0>;
			clocks = <&vdosys1 CLK_VDO1_VPP_MERGE2>,
				 <&vdosys1 CLK_VDO1_MERGE2_DL_ASYNC>;
			clock-names = "merge","merge_async";
			power-domains = <&spm MT8195_POWER_DOMAIN_VDOSYS1>;
			mediatek,gce-client-reg = <&gce0 SUBSYS_1c10XXXX 0xe000 0x1000>;
			mediatek,merge-mute = <1>;
			resets = <&vdosys1 MT8195_VDOSYS1_SW0_RST_B_MERGE2_DL_ASYNC>;
		};

		merge4: disp_vpp_merge@1c10f000 {
			compatible = "mediatek,mt8195-disp-merge";
			reg = <0 0x1c10f000 0 0x1000>;
			interrupts = <GIC_SPI 506 IRQ_TYPE_LEVEL_HIGH 0>;
			clocks = <&vdosys1 CLK_VDO1_VPP_MERGE3>,
				 <&vdosys1 CLK_VDO1_MERGE3_DL_ASYNC>;
			clock-names = "merge","merge_async";
			power-domains = <&spm MT8195_POWER_DOMAIN_VDOSYS1>;
			mediatek,gce-client-reg = <&gce0 SUBSYS_1c10XXXX 0xf000 0x1000>;
			mediatek,merge-mute = <1>;
			resets = <&vdosys1 MT8195_VDOSYS1_SW0_RST_B_MERGE3_DL_ASYNC>;
		};

		merge5: disp_vpp_merge@1c110000 {
			compatible = "mediatek,mt8195-disp-merge";
			reg = <0 0x1c110000 0 0x1000>;
			interrupts = <GIC_SPI 507 IRQ_TYPE_LEVEL_HIGH 0>;
			clocks = <&vdosys1 CLK_VDO1_VPP_MERGE4>,
				 <&vdosys1 CLK_VDO1_MERGE4_DL_ASYNC>;
			clock-names = "merge","merge_async";
			power-domains = <&spm MT8195_POWER_DOMAIN_VDOSYS1>;
			mediatek,gce-client-reg = <&gce0 SUBSYS_1c11XXXX 0x0000 0x1000>;
			mediatek,merge-fifo-en = <1>;
			resets = <&vdosys1 MT8195_VDOSYS1_SW0_RST_B_MERGE4_DL_ASYNC>;
		};

		disp_dpi1: disp_dpi1@1c112000 {
			compatible = "mediatek,mt8195-dpi";
			reg = <0 0x1c112000 0 0x1000>;
			mediatek,vdosys1-dpi = <&vdosys1 0x0>;
			interrupts = <GIC_SPI 512 IRQ_TYPE_LEVEL_HIGH 0>;
			power-domains = <&spm MT8195_POWER_DOMAIN_VDOSYS1>;
			clocks = <&vdosys1 CLK_VDO1_DPI1>,
				 <&vdosys1 CLK_VDO1_DPI1_MM>;
			clock-names = "pixel", "engine";
			status = "disabled";
		};

		dp_intf1: dp_intf1@1c113000 {
			compatible = "mediatek,mt8195-dpintf";
			reg = <0 0x1c113000 0 0x1000>;
			interrupts = <GIC_SPI 513 IRQ_TYPE_LEVEL_HIGH 0>;
			power-domains = <&spm MT8195_POWER_DOMAIN_VDOSYS1>;
			clocks = <&vdosys1 CLK_VDO1_DP_INTF0_MM>,
				 <&vdosys1 CLK_VDO1_DPINTF>,
				 <&topckgen CLK_TOP_DP>,
				 <&apmixedsys CLK_APMIXED_TVDPLL2>,
				 <&topckgen CLK_TOP_TVDPLL2_D2>,
				 <&topckgen CLK_TOP_TVDPLL2_D4>,
				 <&topckgen CLK_TOP_TVDPLL2_D8>,
				 <&topckgen CLK_TOP_TVDPLL2_D16>;
			clock-names = "engine",
				      "ck_cg",
				      "pixel",
				      "pll",
				      "TVDPLL_D2",
				      "TVDPLL_D4",
				      "TVDPLL_D8",
				      "TVDPLL_D16";
			status = "disabled";
		};

		ethdr0: disp_ethdr@1c114000 {
			compatible = "mediatek,mt8195-disp-ethdr";
			reg = <0 0x1c114000 0 0x1000>,
			      <0 0x1c115000 0 0x1000>,
			      <0 0x1c117000 0 0x1000>,
			      <0 0x1c119000 0 0x1000>,
			      <0 0x1c11A000 0 0x1000>,
			      <0 0x1c11B000 0 0x1000>,
			      <0 0x1c11C000 0 0x1000>;
			reg-names = "mixer", "vdo_fe0", "vdo_fe1", "gfx_fe0", "gfx_fe1",
				    "vdo_be", "adl_ds";
			mediatek,gce-client-reg = <&gce0 SUBSYS_1c11XXXX 0x4000 0x1000>,
						  <&gce0 SUBSYS_1c11XXXX 0x5000 0x1000>,
						  <&gce0 SUBSYS_1c11XXXX 0x7000 0x1000>,
						  <&gce0 SUBSYS_1c11XXXX 0x9000 0x1000>,
						  <&gce0 SUBSYS_1c11XXXX 0xA000 0x1000>,
						  <&gce0 SUBSYS_1c11XXXX 0xB000 0x1000>,
						  <&gce0 SUBSYS_1c11XXXX 0xC000 0x1000>;
			clocks = <&vdosys1 CLK_VDO1_DISP_MIXER>,
				 <&vdosys1 CLK_VDO1_HDR_VDO_FE0>,
				 <&vdosys1 CLK_VDO1_HDR_VDO_FE1>,
				 <&vdosys1 CLK_VDO1_HDR_GFX_FE0>,
				 <&vdosys1 CLK_VDO1_HDR_GFX_FE1>,
				 <&vdosys1 CLK_VDO1_HDR_VDO_BE>,
				 <&vdosys1 CLK_VDO1_26M_SLOW>,
				 <&vdosys1 CLK_VDO1_HDR_VDO_FE0_DL_ASYNC>,
				 <&vdosys1 CLK_VDO1_HDR_VDO_FE1_DL_ASYNC>,
				 <&vdosys1 CLK_VDO1_HDR_GFX_FE0_DL_ASYNC>,
				 <&vdosys1 CLK_VDO1_HDR_GFX_FE1_DL_ASYNC>,
				 <&vdosys1 CLK_VDO1_HDR_VDO_BE_DL_ASYNC>,
				 <&topckgen CLK_TOP_ETHDR>;
			clock-names = "mixer", "vdo_fe0", "vdo_fe1", "gfx_fe0", "gfx_fe1",
				      "vdo_be", "adl_ds", "vdo_fe0_async", "vdo_fe1_async",
				      "gfx_fe0_async", "gfx_fe1_async","vdo_be_async",
				      "ethdr_top";
			power-domains = <&spm MT8195_POWER_DOMAIN_VDOSYS1>;
			iommus = <&iommu_vpp M4U_PORT_L3_HDR_DS>,
				 <&iommu_vpp M4U_PORT_L3_HDR_ADL>;
			interrupts = <GIC_SPI 517 IRQ_TYPE_LEVEL_HIGH 0>; /* disp mixer */
			resets = <&vdosys1 MT8195_VDOSYS1_SW1_RST_B_HDR_VDO_FE0_DL_ASYNC>,
				 <&vdosys1 MT8195_VDOSYS1_SW1_RST_B_HDR_VDO_FE1_DL_ASYNC>,
				 <&vdosys1 MT8195_VDOSYS1_SW1_RST_B_HDR_GFX_FE0_DL_ASYNC>,
				 <&vdosys1 MT8195_VDOSYS1_SW1_RST_B_HDR_GFX_FE1_DL_ASYNC>,
				 <&vdosys1 MT8195_VDOSYS1_SW1_RST_B_HDR_VDO_BE_DL_ASYNC>;
		};

		hdmi0: hdmi@1c300000 {
			compatible = "mediatek,mt8195-hdmi";
			reg = <0 0x1c300000 0 0x1000>;
			power-domains = <&spm MT8195_POWER_DOMAIN_HDMI_TX>;
			clocks = <&topckgen CLK_TOP_UNIVPLL_D6_D4>,
				 <&topckgen CLK_TOP_MSDCPLL_D2>,
				 <&topckgen CLK_TOP_HDMI_APB>,
				 <&topckgen CLK_TOP_UNIVPLL_D4_D8>,
				 <&topckgen CLK_TOP_HDCP>,
				 <&topckgen CLK_TOP_HDCP_24M>,
				 <&vppsys1 CLK_VPP1_VPP_SPLIT_HDMI>;
			clock-names = "univpll_d6_d4",
				      "msdcpll_d2",
				      "hdmi_apb_sel",
				      "univpll_d4_d8",
				      "hdcp_sel",
				      "hdcp24_sel",
				      "split_hdmi";
			interrupts = <GIC_SPI 677 IRQ_TYPE_LEVEL_HIGH 0>;
			phys = <&hdmi_phy>;
			phy-names = "hdmi";
			cec = <&cec>;
			ddc-i2c-bus = <&hdmiddc0>;
			status = "disabled";
		};

		edp_tx: edp_tx@1c500000 {
			status = "disabled";
			compatible = "mediatek,mt8195-dp-tx";
			reg = <0 0x1c500000 0 0x8000>;
			nvmem-cells = <&dp_calibration>;
			nvmem-cell-names = "dp_calibration_data";
			power-domains = <&spm MT8195_POWER_DOMAIN_EPD_TX>;
			interrupts = <GIC_SPI 676 IRQ_TYPE_LEVEL_HIGH 0>;
		};

		dp_tx: dp_tx@1c600000 {
			compatible = "mediatek,mt8195-dp-tx";
			reg = <0 0x1c600000 0 0x8000>;
			nvmem-cells = <&dp_calibration>;
			nvmem-cell-names = "dp_calibration_data";
			power-domains = <&spm MT8195_POWER_DOMAIN_DP_TX>;
			interrupts = <GIC_SPI 458 IRQ_TYPE_LEVEL_HIGH 0>;
			status = "disabled";
		};
	};

	hdmiddc0: ddc_i2c {
		compatible = "mediatek,mt8195-hdmi-ddc";
		clocks = <&clk26m>;
		clock-names = "ddc-i2c";
		status = "disabled";
	};

	sound: mt8195-sound {
		mediatek,platform = <&afe>;
		status = "disabled";
	};

	thermal_zones: thermal-zones {
		soc_max {
			polling-delay = <1000>; /* milliseconds */
			polling-delay-passive = <100>; /* milliseconds */
			thermal-sensors = <&lvts 0>;
			sustainable-power = <4000>;

			trips {
				threshold: trip-point@0 {
					temperature = <68000>;
					hysteresis = <2000>;
					type = "passive";
				};

				target: target@1 {
					temperature = <90000>;
					hysteresis = <2000>;
					type = "passive";
				};

				soc_max_crit: soc_max_crit@0 {
					temperature = <115000>;
					hysteresis = <2000>;
					type = "critical";
				};
			};
			cooling-maps {
				map0 {
					trip = <&target>;
					cooling-device = <&cpu0
						THERMAL_NO_LIMIT
						THERMAL_NO_LIMIT>,
								<&cpu1
						THERMAL_NO_LIMIT
						THERMAL_NO_LIMIT>,
								<&cpu2
						THERMAL_NO_LIMIT
						THERMAL_NO_LIMIT>,
								<&cpu3
						THERMAL_NO_LIMIT
						THERMAL_NO_LIMIT>;
					contribution = <3072>;
				};
				map1 {
					trip = <&target>;
					cooling-device = <&cpu4
						THERMAL_NO_LIMIT
						THERMAL_NO_LIMIT>,
								<&cpu5
						THERMAL_NO_LIMIT
						THERMAL_NO_LIMIT>,
								<&cpu6
						THERMAL_NO_LIMIT
						THERMAL_NO_LIMIT>,
								<&cpu7
						THERMAL_NO_LIMIT
						THERMAL_NO_LIMIT>;
					contribution = <1024>;
				};
			};
		};
		cpu_big1 {
			polling-delay = <0>; /* milliseconds */
			polling-delay-passive = <0>; /* milliseconds */
			thermal-sensors = <&lvts 1>;
		};
		cpu_big2 {
			polling-delay = <0>; /* milliseconds */
			polling-delay-passive = <0>; /* milliseconds */
			thermal-sensors = <&lvts 2>;
		};
		cpu_big3 {
			polling-delay = <0>; /* milliseconds */
			polling-delay-passive = <0>; /* milliseconds */
			thermal-sensors = <&lvts 3>;
		};
		cpu_big4 {
			polling-delay = <0>; /* milliseconds */
			polling-delay-passive = <0>; /* milliseconds */
			thermal-sensors = <&lvts 4>;
		};
		cpu_little1{
			polling-delay = <0>; /* milliseconds */
			polling-delay-passive = <0>; /* milliseconds */
			thermal-sensors = <&lvts 5>;
		};
		cpu_little2 {
			polling-delay = <0>; /* milliseconds */
			polling-delay-passive = <0>; /* milliseconds */
			thermal-sensors = <&lvts 6>;
		};
		cpu_little3 {
			polling-delay = <0>; /* milliseconds */
			polling-delay-passive = <0>; /* milliseconds */
			thermal-sensors = <&lvts 7>;
		};
		cpu_little4 {
			polling-delay = <0>; /* milliseconds */
			polling-delay-passive = <0>; /* milliseconds */
			thermal-sensors = <&lvts 8>;
		};
		vpu1 {
			polling-delay = <0>; /* milliseconds */
			polling-delay-passive = <0>; /* milliseconds */
			thermal-sensors = <&lvts 9>;
		};
		vpu2 {
			polling-delay = <0>; /* milliseconds */
			polling-delay-passive = <0>; /* milliseconds */
			thermal-sensors = <&lvts 10>;
		};
		gpu1 {
			polling-delay = <0>; /* milliseconds */
			polling-delay-passive = <0>; /* milliseconds */
			thermal-sensors = <&lvts 11>;
		};
		gpu2 {
			polling-delay = <0>; /* milliseconds */
			polling-delay-passive = <0>; /* milliseconds */
			thermal-sensors = <&lvts 12>;
		};
		vdec {
			polling-delay = <0>; /* milliseconds */
			polling-delay-passive = <0>; /* milliseconds */
			thermal-sensors = <&lvts 13>;
		};
		img {
			polling-delay = <0>; /* milliseconds */
			polling-delay-passive = <0>; /* milliseconds */
			thermal-sensors = <&lvts 14>;
		};
		infra {
			polling-delay = <0>; /* milliseconds */
			polling-delay-passive = <0>; /* milliseconds */
			thermal-sensors = <&lvts 15>;
		};
		cam1 {
			polling-delay = <0>; /* milliseconds */
			polling-delay-passive = <0>; /* milliseconds */
			thermal-sensors = <&lvts 16>;
		};
		cam2 {
			polling-delay = <0>; /* milliseconds */
			polling-delay-passive = <0>; /* milliseconds */
			thermal-sensors = <&lvts 17>;
		};
	};
};
